VERSION ""

NS_ :

BS_:

BU_: FCM CGW EPS IPB TBOX
BO_ 773 FRM_3: 8 FCM
  SG_ FRM_3_VSetDis : 7|9@0+ (0.5,0) [0|255.5] "KPH" CGW
  SG_ FRM_3_DxTarObj : 14|3@0+ (1,0) [0|7] "Bit" CGW
  SG_ FRM_3_ObjValid : 8|1@0+ (1,0) [0|1] "Bit" CGW
  SG_ FRM_3_FrontObject_Type : 11|3@0+ (1,0) [0|7] "Bit" CGW
  SG_ FRM_3_Textinfo : 23|5@0+ (1,0) [0|31] "Bit" CGW
  SG_ FRM_3_TakeOverReq : 18|1@0+ (1,0) [0|1] "Bit" CGW
  SG_ FRM_3_TimeGapSet_ICM : 17|2@0+ (1,0) [0|3] "Bit" CGW
  SG_ FRM_3_ACCMode : 37|4@0+ (1,0) [0|15] "Bit" CGW
  SG_ FRM_3_Obiect_Dx : 29|8@0+ (0.5,0) [0|127] "M" CGW
  SG_ FRM_3_FCWMode : 33|3@0+ (1,0) [0|7] "Bit" CGW
  SG_ FRM_3_AEBMode : 46|3@0+ (1,0) [0|7] "Bit" CGW
  SG_ FRM_3_DistanceWarning : 43|1@0+ (1,0) [0|1] "Bit" CGW
  SG_ FRM_3_FCW_PreWarning : 42|1@0+ (1,0) [0|1] "Bit" CGW
  SG_ FRM_3_FCW_ON_OFF_Sts : 40|1@0+ (1,0) [0|1] "Bit" CGW
  SG_ FRM_3_FCW_OPTION_Sts : 55|2@0+ (1,0) [0|3] "Bit" CGW
  SG_ FRM_3_AEB_ON_OFF_Sts : 53|1@0+ (1,0) [0|1] "Bit" CGW
  SG_ FRM_3_MessageCounter : 51|4@0+ (1,0) [0|15] "Bit" CGW
  SG_ FRM_3_CRC : 63|8@0+ (1,0) [0|255] "Bit" CGW

BO_ 775 FCM_2: 8 FCM
  SG_ FCM_2_HMA_Status : 2|3@0+ (1,0) [0|7] "Bit" CGW
  SG_ FCM_2_HMA_HighbeamReq : 3|1@0+ (1,0) [0|1] "Bit" CGW
  SG_ FCM_2_HMAOnOffsts : 5|2@0+ (1,0) [0|3] "Bit" CGW
  SG_ FCM_2_LDW_LKA_LeftVisualization : 7|2@0+ (1,0) [0|3] "Bit" CGW
  SG_ FCM_2_LDW_LKA_RightVisualization : 15|2@0+ (1,0) [0|3] "Bit" CGW
  SG_ FCM_2_TrailorModeSts : 10|2@0+ (1,0) [0|3] "" CGW
  SG_ FCM_2_LDP_Status : 13|3@0+ (1,0) [0|7] "Bit" CGW
  SG_ FCM_2_LDWLKA_Sensitivityfeedback : 8|2@0+ (1,0) [0|3] "Bit" CGW
  SG_ FCM_2_SLAState : 21|3@0+ (1,0) [0|7] "Bit" CGW
  SG_ FCM_2_SLASpdlimit : 18|8@0+ (1,0) [0|255] "Bit" CGW
  SG_ FCM_2_SLAOnOffsts : 26|2@0+ (1,0) [0|3] "Bit" CGW
  SG_ FCM_2_SLASpdlimitWarning : 24|1@0+ (1,0) [0|1] "Bit" CGW
  SG_ FCM_2_Camera_Textinfo : 39|2@0+ (1,0) [0|3] "Bit" CGW
  SG_ FCM_2_ADAS_TakeoverReq : 37|2@0+ (1,0) [0|3] "Bit" CGW
  SG_ FCM_2_TJA_ICA_Textinfo : 34|3@0+ (1,0) [0|7] "Bit" CGW
  SG_ FCM_2_TJA_ICA_Mode : 47|3@0+ (1,0) [0|7] "Bit" CGW
  SG_ FCM_2_LDWOnOffSts : 43|2@0+ (1,0) [0|3] "Bit" CGW
  SG_ FCM_2_MessageCounter : 51|4@0+ (1,0) [0|15] "Bit" CGW
  SG_ FCM_2_weather_signal : 53|2@0+ (1,0) [0|3] "" CGW,TBOX
  SG_ FCM_2_CRCCheck : 63|8@0+ (1,0) [0|255] "Bit" CGW

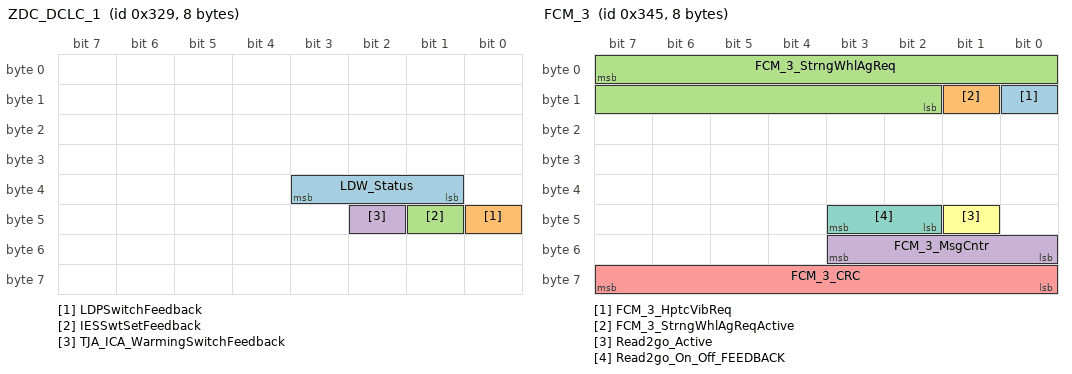
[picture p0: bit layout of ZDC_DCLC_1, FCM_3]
BO_ 809 ZDC_DCLC_1: 8 FCM
  SG_ LDW_Status : 35|3@0+ (1,0) [0|7] "Bit" Vector__XXX
  SG_ LDPSwitchFeedback : 40|1@0+ (1,0) [0|1] "Bit" Vector__XXX
  SG_ IESSwtSetFeedback : 41|1@0+ (1,0) [0|1] "Bit" Vector__XXX
  SG_ TJA_ICA_WarmingSwitchFeedback : 42|1@0+ (1,0) [0|1] "Bit" Vector__XXX

BO_ 837 FCM_3: 8 FCM
  SG_ FCM_3_HptcVibReq : 8|1@0+ (1,0) [0|1] "Bit" CGW,EPS
  SG_ FCM_3_StrngWhlAgReqActive : 9|1@0+ (1,0) [0|1] "Bit" EPS
  SG_ FCM_3_StrngWhlAgReq : 7|14@0+ (0.1,-780) [-780|780] "deg" EPS
  SG_ FCM_3_MsgCntr : 51|4@0+ (1,0) [0|15] "Bit" EPS
  SG_ FCM_3_CRC : 63|8@0+ (1,0) [0|255] "Bit" EPS,IPB
  SG_ Read2go_Active : 41|1@0+ (1,0) [0|1] "Bit" Vector__XXX
  SG_ Read2go_On_Off_FEEDBACK : 43|2@0+ (1,0) [0|3] "Bit" Vector__XXX

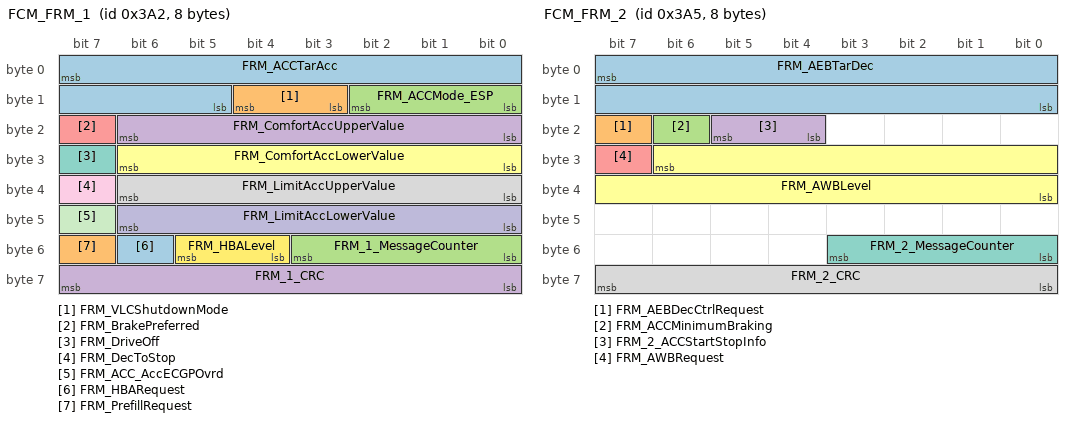
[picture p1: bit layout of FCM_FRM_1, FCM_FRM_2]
BO_ 930 FCM_FRM_1: 8 FCM
  SG_ FRM_ACCTarAcc : 7|11@0+ (0.005,-5) [-5|5.235] "M_S2" IPB
  SG_ FRM_VLCShutdownMode : 12|2@0+ (1,0) [0|3] "Bit" IPB
  SG_ FRM_ACCMode_ESP : 10|3@0+ (1,0) [0|7] "Bit" IPB
  SG_ FRM_ComfortAccUpperValue : 22|7@0+ (0.025,0) [0|3.125] "M_S2" IPB
  SG_ FRM_BrakePreferred : 23|1@0+ (1,0) [0|1] "Bit" IPB
  SG_ FRM_ComfortAccLowerValue : 30|7@0+ (0.025,0) [0|3.125] "M_S2" IPB
  SG_ FRM_DriveOff : 31|1@0+ (1,0) [0|1] "Bit" IPB
  SG_ FRM_LimitAccUpperValue : 38|7@0+ (0.1,0) [0|12.7] "M_S2" IPB
  SG_ FRM_DecToStop : 39|1@0+ (1,0) [0|1] "Bit" IPB
  SG_ FRM_LimitAccLowerValue : 46|7@0+ (0.1,-12.7) [-12.7|0] "M_S2" IPB
  SG_ FRM_ACC_AccECGPOvrd : 47|1@0+ (1,0) [0|1] "Bit" IPB
  SG_ FRM_HBALevel : 53|2@0+ (1,0) [0|3] "Bit" IPB
  SG_ FRM_HBARequest : 54|1@0+ (1,0) [0|1] "Bit" IPB
  SG_ FRM_PrefillRequest : 55|1@0+ (1,0) [0|1] "Bit" IPB
  SG_ FRM_1_MessageCounter : 51|4@0+ (1,0) [0|15] "Bit" IPB
  SG_ FRM_1_CRC : 63|8@0+ (1,0) [0|255] "Bit" IPB

BO_ 933 FCM_FRM_2: 8 FCM
  SG_ FRM_AEBTarDec : 7|16@0+ (0.0004882,-16) [-16|15.994187] "M_S2" IPB,CGW
  SG_ FRM_AEBDecCtrlRequest : 23|1@0+ (1,0) [0|1] "Bit" IPB,CGW
  SG_ FRM_ACCMinimumBraking : 22|1@0+ (1,0) [0|1] "Bit" IPB,CGW
  SG_ FRM_2_ACCStartStopInfo : 21|2@0+ (1,0) [0|3] "Bit" IPB,CGW
  SG_ FRM_AWBRequest : 31|1@0+ (1,0) [0|1] "Bit" IPB,CGW
  SG_ FRM_AWBLevel : 30|15@0+ (1,0) [0|15] "Bit" IPB,CGW
  SG_ FRM_2_MessageCounter : 51|4@0+ (1,0) [0|15] "Bit" IPB,CGW
  SG_ FRM_2_CRC : 63|8@0+ (1,0) [0|255] "Bit" IPB,CGW

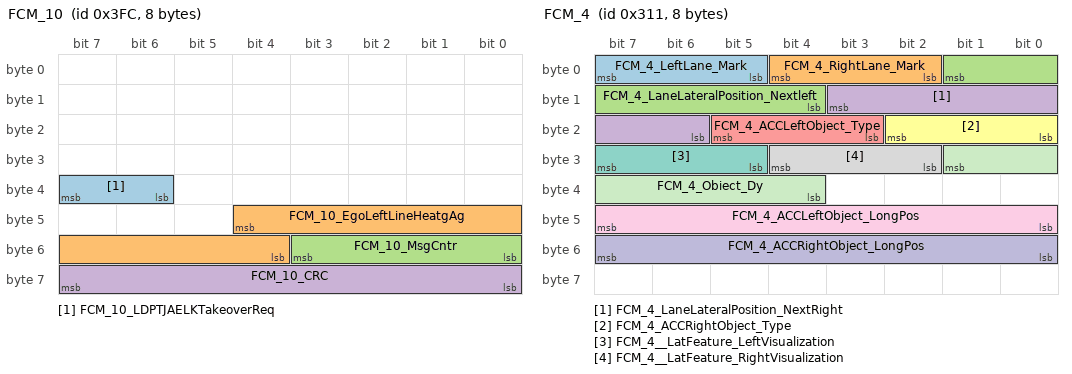
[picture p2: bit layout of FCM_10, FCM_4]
BO_ 1020 FCM_10: 8 FCM
  SG_ FCM_10_LDPTJAELKTakeoverReq : 39|2@0+ (1,0) [0|3] "Bit" CGW
  SG_ FCM_10_EgoLeftLineHeatgAg : 44|9@0+ (0.004,-1.02) [-1.02|1.02] "Rad" CGW
  SG_ FCM_10_MsgCntr : 51|4@0+ (1,0) [0|15] "Bit" CGW
  SG_ FCM_10_CRC : 63|8@0+ (1,0) [0|255] "Bit" CGW

BO_ 777 FCM_3_G: 8 FCM
  SG_ LaneCurvatureRadius : 7|11@0+ (0.00001,-0.01023) [-0.01023|0.01024] "Bit" CGW
  SG_ FCM_3_ACCLeftObjectDetected : 9|2@0+ (1,0) [0|3] "Bit" CGW
  SG_ FCM_3_ACCRightObjectDetected : 11|2@0+ (1,0) [0|3] "Bit" CGW
  SG_ FCM_3_ACCLeftObject_LatPos : 21|6@0+ (0.2,0) [0|12.6] "Bit" CGW
  SG_ FCM_3_ACCRightObject_LatPos : 29|6@0+ (0.2,0) [0|12.6] "Bit" CGW
  SG_ FCM_3_FrontObject_IndicatorRight : 22|1@0+ (1,0) [0|1] "Bit" CGW
  SG_ FCM_3_FrontObject_IndicatorLeft : 23|1@0+ (1,0) [0|1] "Bit" CGW
  SG_ FCM_3_FrontObject_BrakeLamp : 30|1@0+ (1,0) [0|1] "Bit" CGW
  SG_ FCM_3_LeftLane_C0 : 37|6@0+ (0.2,0) [0|12.6] "Bit" CGW
  SG_ FCM_3_RightLane_C0 : 47|6@0+ (0.2,0) [0|12.6] "Bit" CGW
  SG_ FCM_3_NoLeftTurn_sign : 38|1@0+ (1,0) [0|1] "Bit" CGW
  SG_ FCM_3_NoRightTurn_sign : 39|1@0+ (1,0) [0|1] "Bit" CGW
  SG_ FCM_3_StopSign : 31|1@0+ (1,0) [0|1] "Bit" CGW
  SG_ FCM_3_NOU_turnsign : 41|1@0+ (1,0) [0|1] "Bit" CGW
  SG_ FCM_3_Noentrysign : 40|1@0+ (1,0) [0|1] "Bit" CGW
  SG_ FCM_3_Constructionareasign : 55|1@0+ (1,0) [0|1] "Bit" CGW
  SG_ FCM_3_Crossingsign : 54|1@0+ (1,0) [0|1] "Bit" CGW
  SG_ FCM_3_YieldSIgn : 53|1@0+ (1,0) [0|1] "Bit" CGW
  SG_ FCM_3_NextLeftLane_Mark : 58|3@0+ (1,0) [0|7] "Bit" CGW
  SG_ FCM_3_NextRightLane_Mark : 61|3@0+ (1,0) [0|7] "Bit" CGW

BO_ 785 FCM_4: 8 FCM
  SG_ FCM_4_LeftLane_Mark : 7|3@0+ (1,0) [0|7] "Bit" CGW
  SG_ FCM_4_RightLane_Mark : 4|3@0+ (1,0) [0|7] "Bit" CGW
  SG_ FCM_4_LaneLateralPosition_Nextleft : 1|6@0+ (0.2,0) [0|12.6] "Bit" CGW
  SG_ FCM_4_LaneLateralPosition_NextRight : 11|6@0+ (0.2,0) [0|12.6] "Bit" CGW
  SG_ FCM_4_ACCLeftObject_Type : 21|3@0+ (1,0) [0|7] "Bit" CGW
  SG_ FCM_4_ACCRightObject_Type : 18|3@0+ (1,0) [0|7] "Bit" CGW
  SG_ FCM_4__LatFeature_LeftVisualization : 31|3@0+ (1,0) [0|7] "Bit" CGW
  SG_ FCM_4__LatFeature_RightVisualization : 28|3@0+ (1,0) [0|7] "Bit" CGW
  SG_ FCM_4_ACCLeftObject_LongPos : 47|8@0+ (1,0) [0|255] "Bit" CGW
  SG_ FCM_4_ACCRightObject_LongPos : 55|8@0+ (1,0) [0|255] "Bit" CGW
  SG_ FCM_4_Obiect_Dy : 25|6@0+ (0.1,-3.2) [-3.2|3.1] "M" CGW

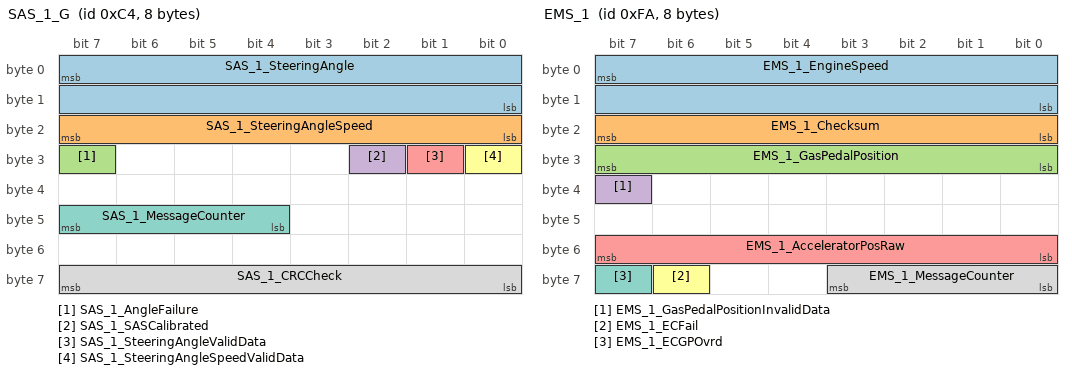
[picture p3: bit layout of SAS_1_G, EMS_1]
BO_ 196 SAS_1_G: 8 CGW
  SG_ SAS_1_SteeringAngle : 7|16@0+ (0.0625,-2048) [-2048|2047.9375] "Deg" FCM
  SG_ SAS_1_SteeringAngleSpeed : 23|8@0+ (4,0) [0|1016] "Deg_Sec" FCM
  SG_ SAS_1_AngleFailure : 31|1@0+ (1,0) [0|1] "Bit" FCM
  SG_ SAS_1_SASCalibrated : 26|1@0+ (1,0) [0|1] "Bit" FCM
  SG_ SAS_1_SteeringAngleValidData : 25|1@0+ (1,0) [0|1] "Bit" FCM
  SG_ SAS_1_SteeringAngleSpeedValidData : 24|1@0+ (1,0) [0|1] "Bit" FCM
  SG_ SAS_1_MessageCounter : 47|4@0+ (1,0) [0|15] "Bit" FCM
  SG_ SAS_1_CRCCheck : 63|8@0+ (1,0) [0|255] "Bit" FCM

BO_ 250 EMS_1: 8 CGW
  SG_ EMS_1_EngineSpeed : 7|16@0+ (0.25,0) [0|16383] "Rpm" FCM
  SG_ EMS_1_Checksum : 23|8@0+ (1,0) [0|255] "Bit" FCM
  SG_ EMS_1_GasPedalPosition : 31|8@0+ (0.392,0) [0|99.568] "%" FCM
  SG_ EMS_1_GasPedalPositionInvalidData : 39|1@0+ (1,0) [0|1] "Bit" FCM
  SG_ EMS_1_AcceleratorPosRaw : 55|8@0+ (0.392,0) [0|99.568] "%" FCM
  SG_ EMS_1_ECFail : 62|1@0+ (1,0) [0|1] "Bit" FCM
  SG_ EMS_1_ECGPOvrd : 63|1@0+ (1,0) [0|1] "Bit" FCM
  SG_ EMS_1_MessageCounter : 59|4@0+ (1,0) [0|15] "Bit" FCM

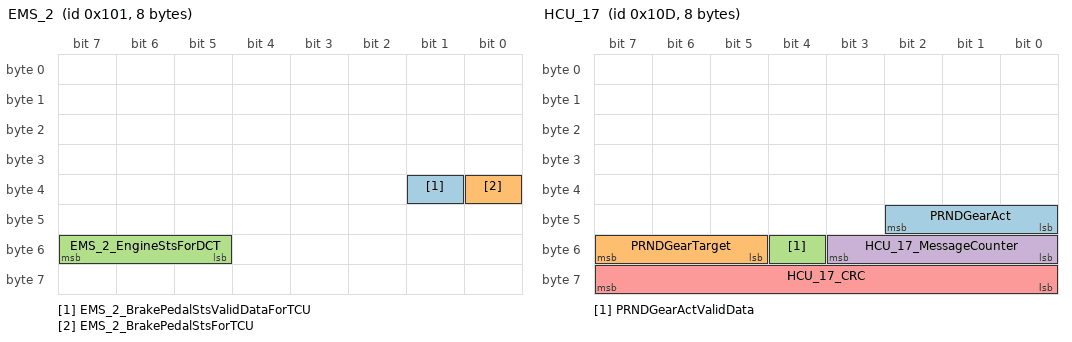
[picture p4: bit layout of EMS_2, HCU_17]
BO_ 257 EMS_2: 8 CGW
  SG_ EMS_2_BrakePedalStsValidDataForTCU : 33|1@0+ (1,0) [0|1] "Bit" FCM
  SG_ EMS_2_BrakePedalStsForTCU : 32|1@0+ (1,0) [0|1] "Bit" FCM
  SG_ EMS_2_EngineStsForDCT : 55|3@0+ (1,0) [0|7] "Bit" FCM

BO_ 269 HCU_17: 8 CGW
  SG_ PRNDGearAct : 42|3@0+ (1,0) [0|7] "Bit" FCM
  SG_ PRNDGearTarget : 55|3@0+ (1,0) [0|7] "Bit" FCM
  SG_ PRNDGearActValidData : 52|1@0+ (1,0) [0|1] "Bit" FCM
  SG_ HCU_17_MessageCounter : 51|4@0+ (1,0) [0|15] "Bit" FCM
  SG_ HCU_17_CRC : 63|8@0+ (1,0) [0|255] "Bit" FCM

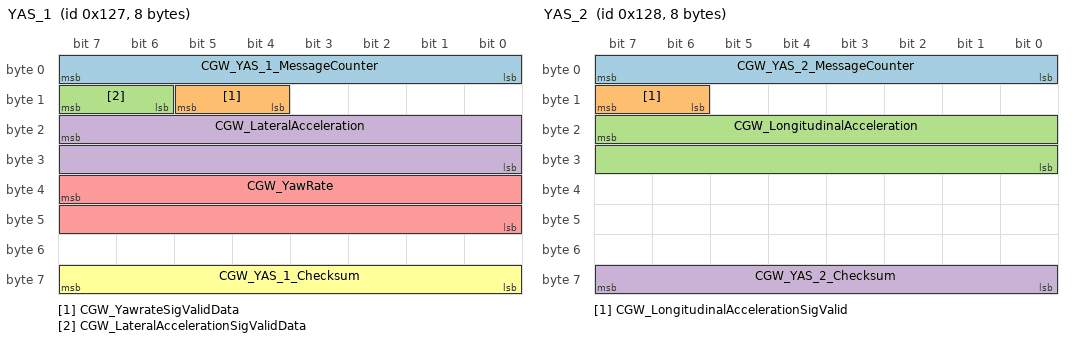
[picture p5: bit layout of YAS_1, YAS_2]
BO_ 295 YAS_1: 8 CGW
  SG_ CGW_YAS_1_MessageCounter : 7|8@0+ (1,0) [0|255] "Bit" FCM
  SG_ CGW_YawrateSigValidData : 13|2@0+ (1,0) [0|3] "Bit" FCM
  SG_ CGW_LateralAccelerationSigValidData : 15|2@0+ (1,0) [0|3] "Bit" FCM
  SG_ CGW_LateralAcceleration : 23|16@0+ (0.001,-2) [-2|2] "G" FCM
  SG_ CGW_YawRate : 39|16@0+ (0.01,-180) [-180|180] "Deg/sec" FCM
  SG_ CGW_YAS_1_Checksum : 63|8@0+ (1,0) [0|255] "Bit" FCM

BO_ 296 YAS_2: 8 CGW
  SG_ CGW_YAS_2_MessageCounter : 7|8@0+ (1,0) [0|255] "Bit" FCM
  SG_ CGW_LongitudinalAccelerationSigValid : 15|2@0+ (1,0) [0|3] "Bit" FCM
  SG_ CGW_LongitudinalAcceleration : 23|16@0+ (0.001,-2) [-2|2] "G" FCM
  SG_ CGW_YAS_2_Checksum : 63|8@0+ (1,0) [0|255] "Bit" FCM

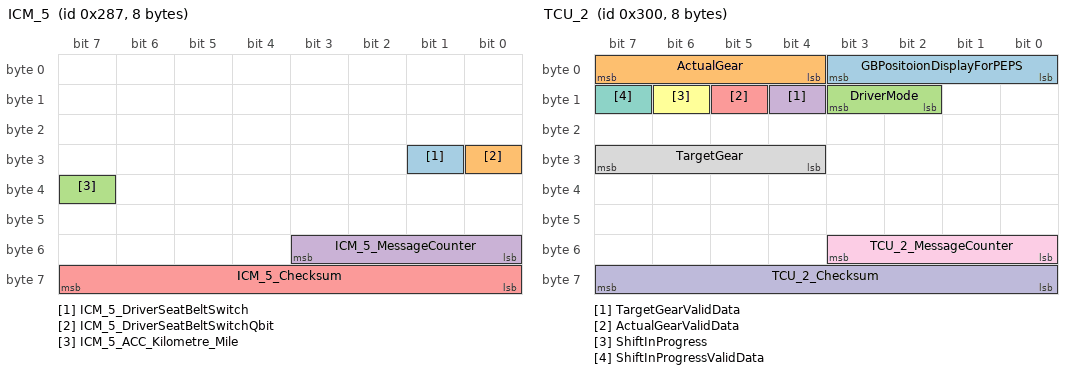
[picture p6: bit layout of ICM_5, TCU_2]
BO_ 647 ICM_5: 8 CGW
  SG_ ICM_5_DriverSeatBeltSwitch : 25|1@0+ (1,0) [0|1] "Bit" FCM
  SG_ ICM_5_DriverSeatBeltSwitchQbit : 24|1@0+ (1,0) [0|1] "Bit" FCM
  SG_ ICM_5_ACC_Kilometre_Mile : 39|1@0+ (1,0) [0|1] "Bit" FCM
  SG_ ICM_5_MessageCounter : 51|4@0+ (1,0) [0|15] "Bit" FCM
  SG_ ICM_5_Checksum : 63|8@0+ (1,0) [0|255] "Bit" FCM

BO_ 768 TCU_2: 8 CGW
  SG_ GBPositoionDisplayForPEPS : 3|4@0+ (1,0) [0|15] "Bit" FCM
  SG_ ActualGear : 7|4@0+ (1,0) [0|15] "Bit" FCM
  SG_ DriverMode : 11|2@0+ (1,0) [0|3] "Bit" FCM
  SG_ TargetGearValidData : 12|1@0+ (1,0) [0|1] "Bit" FCM
  SG_ ActualGearValidData : 13|1@0+ (1,0) [0|1] "Bit" FCM
  SG_ ShiftInProgress : 14|1@0+ (1,0) [0|1] "Bit" FCM
  SG_ ShiftInProgressValidData : 15|1@0+ (1,0) [0|1] "Bit" FCM
  SG_ TargetGear : 31|4@0+ (1,0) [0|15] "Bit" FCM
  SG_ TCU_2_MessageCounter : 51|4@0+ (1,0) [0|15] "Bit" FCM
  SG_ TCU_2_Checksum : 63|8@0+ (1,0) [0|255] "Bit" FCM

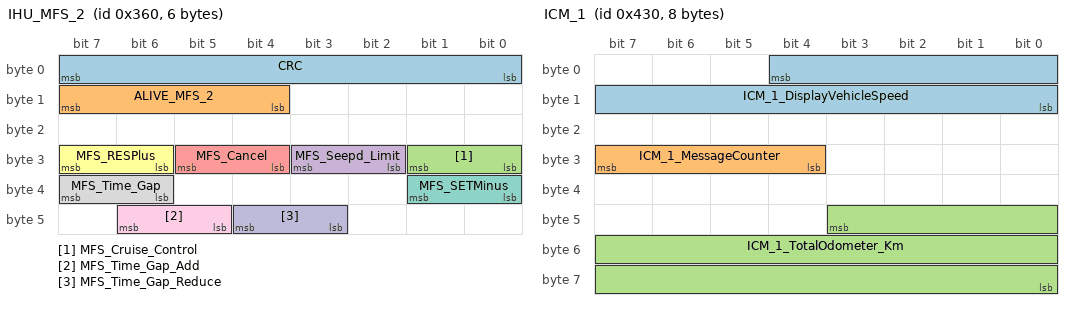
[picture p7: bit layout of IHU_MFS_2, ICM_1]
BO_ 864 IHU_MFS_2: 6 CGW
  SG_ CRC : 7|8@0+ (1,0) [0|255] "Bit" FCM
  SG_ ALIVE_MFS_2 : 15|4@0+ (1,0) [0|15] "Bit" FCM
  SG_ MFS_Cruise_Control : 25|2@0+ (1,0) [0|3] "Bit" FCM
  SG_ MFS_Seepd_Limit : 27|2@0+ (1,0) [0|3] "Bit" FCM
  SG_ MFS_Cancel : 29|2@0+ (1,0) [0|3] "Bit" FCM
  SG_ MFS_RESPlus : 31|2@0+ (1,0) [0|3] "Bit" FCM
  SG_ MFS_SETMinus : 33|2@0+ (1,0) [0|3] "Bit" FCM
  SG_ MFS_Time_Gap : 39|2@0+ (1,0) [0|3] "Bit" FCM
  SG_ MFS_Time_Gap_Add : 46|2@0+ (1,0) [0|3] "Bit" FCM
  SG_ MFS_Time_Gap_Reduce : 44|2@0+ (1,0) [0|3] "Bit" FCM

BO_ 913 BCM_1: 8 CGW
  SG_ BCM_1_HighBeamSts : 2|1@0+ (1,0) [0|1] "Bit" FCM
  SG_ BCM_1_LowBeamSts : 3|1@0+ (1,0) [0|1] "Bit" FCM
  SG_ BCM_1_KeySts : 6|2@0+ (1,0) [0|3] "Bit" FCM
  SG_ BCM_1_Checksum : 15|8@0+ (1,0) [0|255] "Bit" FCM
  SG_ BCM_1_DirectionIndRight : 16|1@0+ (1,0) [0|1] "Bit" FCM
  SG_ BCM_1_DirectionIndLeft : 17|1@0+ (1,0) [0|1] "Bit" FCM
  SG_ BCM_1_HazardLightSW : 18|1@0+ (1,0) [0|1] "Bit" FCM
  SG_ BCM_1_AutoLightSW : 19|1@0+ (1,0) [0|1] "Bit" FCM
  SG_ BCM_1_DriverDoorSts : 24|1@0+ (1,0) [0|1] "Bit" FCM
  SG_ BCM_1_PsngrDoorSts : 25|1@0+ (1,0) [0|1] "Bit" FCM
  SG_ BCM_1_HoodSts : 26|1@0+ (1,0) [0|1] "Bit" FCM
  SG_ BCM_1_RHRDoorSts : 28|1@0+ (1,0) [0|1] "Bit" FCM
  SG_ BCM_1_LHRdoorSts : 29|1@0+ (1,0) [0|1] "Bit" FCM
  SG_ BCM_1_TrunkSts : 30|1@0+ (1,0) [0|1] "Bit" FCM
  SG_ BCM_1_DriverDoorStsQbit : 31|1@0+ (1,0) [0|1] "Bit" FCM
  SG_ BCM_1_HMASW : 32|1@0+ (1,0) [0|1] "Bit" FCM
  SG_ BCM_1_FrontFogLightSts : 37|1@0+ (1,0) [0|1] "Bit" FCM
  SG_ BCM_1_HighBeamSWSts : 38|1@0+ (1,0) [0|1] "Bit" FCM
  SG_ BCM_1_FlashSWSts : 39|1@0+ (1,0) [0|1] "Bit" FCM
  SG_ BCM_1_WiperSts : 47|2@0+ (1,0) [0|3] "Bit" FCM
  SG_ BCM_1_AutoHighSpeedRequest : 52|1@0+ (1,0) [0|1] "Bit" FCM
  SG_ BCM_1_RainDetected : 53|1@0+ (1,0) [0|1] "Bit" FCM
  SG_ BCM_1_MessageCounter : 51|4@0+ (1,0) [0|15] "Bit" FCM

BO_ 1034 HCU_1_G: 8 CGW
  SG_ HCU_PTReady : 49|1@0+ (1,0) [0|1] "Bit" FCM

BO_ 1072 ICM_1: 8 CGW
  SG_ ICM_1_DisplayVehicleSpeed : 4|13@0+ (0.0625,0) [0|511.875] "Km/h" FCM
  SG_ ICM_1_MessageCounter : 31|4@0+ (1,0) [0|15] "Bit" FCM
  SG_ ICM_1_TotalOdometer_Km : 43|20@0+ (1,0) [0|999999] "Km" FCM

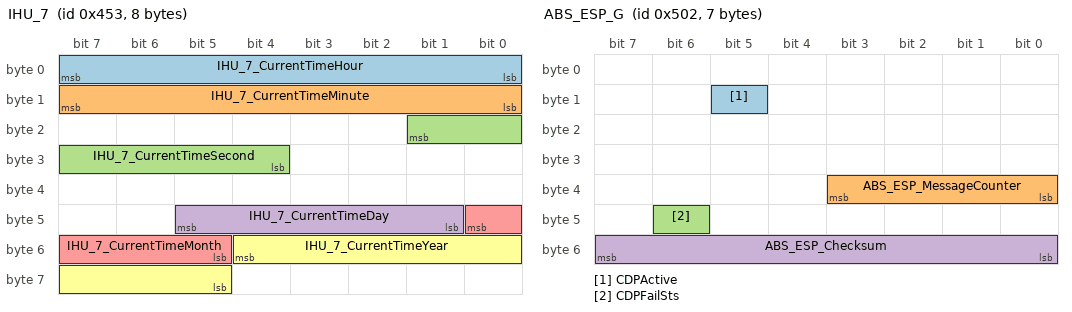
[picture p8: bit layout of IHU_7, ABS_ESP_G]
BO_ 1107 IHU_7: 8 CGW
  SG_ IHU_7_CurrentTimeHour : 7|8@0+ (1,0) [0|23] "Hour" FCM
  SG_ IHU_7_CurrentTimeMinute : 15|8@0+ (1,0) [0|59] "Minute" FCM
  SG_ IHU_7_CurrentTimeSecond : 17|6@0+ (1,0) [0|59] "Second" FCM
  SG_ IHU_7_CurrentTimeDay : 45|5@0+ (1,0) [1|31] "Day" FCM
  SG_ IHU_7_CurrentTimeMonth : 40|4@0+ (1,0) [0|12] "Month" FCM
  SG_ IHU_7_CurrentTimeYear : 52|8@0+ (1,2000) [2000|2255] "Year" FCM

BO_ 1282 ABS_ESP_G: 7 CGW
  SG_ CDPActive : 13|1@0+ (1,0) [0|1] "Bit" FCM
  SG_ ABS_ESP_MessageCounter : 35|4@0+ (1,0) [0|15] "Bit" FCM
  SG_ CDPFailSts : 46|1@0+ (1,0) [0|1] "Bit" FCM
  SG_ ABS_ESP_Checksum : 55|8@0+ (1,0) [0|255] "Bit" FCM

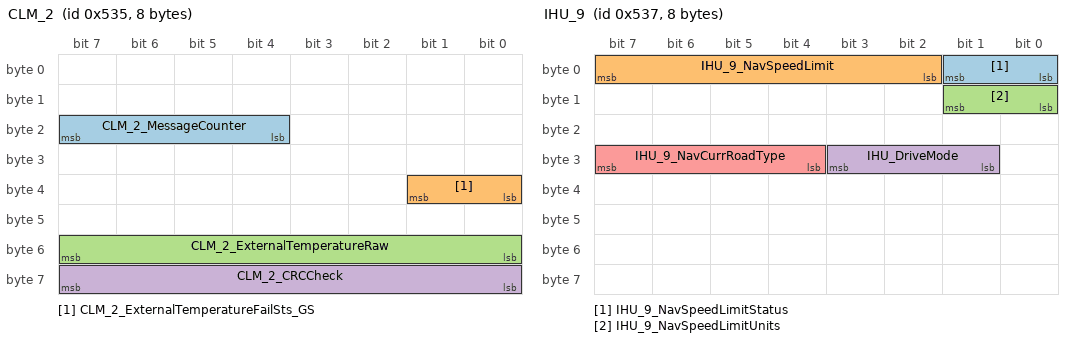
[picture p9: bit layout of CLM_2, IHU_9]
BO_ 1333 CLM_2: 8 CGW
  SG_ CLM_2_MessageCounter : 23|4@0+ (1,0) [0|15] "Bit" FCM
  SG_ CLM_2_ExternalTemperatureFailSts_GS : 33|2@0+ (1,0) [0|3] "Bit" FCM
  SG_ CLM_2_ExternalTemperatureRaw : 55|8@0+ (0.5,-40) [-40|85] "Nm" FCM
  SG_ CLM_2_CRCCheck : 63|8@0+ (1,0) [0|255] "Bit" FCM

BO_ 1335 IHU_9: 8 CGW
  SG_ IHU_9_NavSpeedLimitStatus : 1|2@0+ (1,0) [0|3] "Bit" FCM
  SG_ IHU_9_NavSpeedLimit : 7|6@0+ (1,0) [0|63] "Bit" FCM
  SG_ IHU_9_NavSpeedLimitUnits : 9|2@0+ (1,0) [0|3] "Bit" FCM
  SG_ IHU_DriveMode : 27|3@0+ (1,0) [0|7] "Bit" FCM
  SG_ IHU_9_NavCurrRoadType : 31|4@0+ (1,0) [0|15] "Bit" FCM

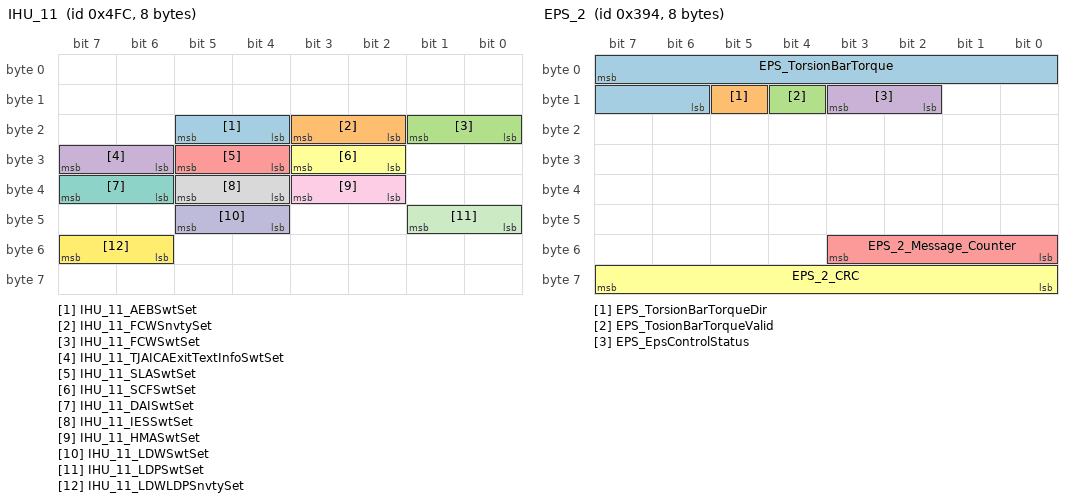
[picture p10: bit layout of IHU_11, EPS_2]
BO_ 1276 IHU_11: 8 CGW
  SG_ IHU_11_AEBSwtSet : 21|2@0+ (1,0) [0|3] "Bit" FCM
  SG_ IHU_11_FCWSnvtySet : 19|2@0+ (1,0) [0|3] "Bit" FCM
  SG_ IHU_11_FCWSwtSet : 17|2@0+ (1,0) [0|3] "Bit" FCM
  SG_ IHU_11_TJAICAExitTextInfoSwtSet : 31|2@0+ (1,0) [0|3] "Bit" FCM
  SG_ IHU_11_SLASwtSet : 29|2@0+ (1,0) [0|3] "Bit" FCM
  SG_ IHU_11_SCFSwtSet : 27|2@0+ (1,0) [0|3] "Bit" FCM
  SG_ IHU_11_DAISwtSet : 39|2@0+ (1,0) [0|3] "Bit" FCM
  SG_ IHU_11_IESSwtSet : 37|2@0+ (1,0) [0|3] "Bit" FCM
  SG_ IHU_11_HMASwtSet : 35|2@0+ (1,0) [0|3] "Bit" FCM
  SG_ IHU_11_LDWSwtSet : 45|2@0+ (1,0) [0|3] "Bit" FCM
  SG_ IHU_11_LDPSwtSet : 41|2@0+ (1,0) [0|3] "Bit" FCM
  SG_ IHU_11_LDWLDPSnvtySet : 55|2@0+ (1,0) [0|3] "Bit" FCM

BO_ 932 ABS_ESP_18: 8 CGW
  SG_ ESP_18_CCO_Active : 1|2@0+ (1,0) [0|3] "" FCM

BO_ 1487 TRM_1: 8 CGW
  SG_ TRM_1_MotorHomeConnectSts : 6|1@0+ (1,0) [0|1] "Bit" FCM
  SG_ TRM_1_RollingCounter : 51|4@0+ (1,0) [0|15] "" FCM

BO_ 916 EPS_2: 8 EPS
  SG_ EPS_TorsionBarTorque : 7|10@0+ (0.01,0) [0|10.22] "Nm" FCM
  SG_ EPS_TorsionBarTorqueDir : 13|1@0+ (1,0) [0|1] "Bit" FCM
  SG_ EPS_TosionBarTorqueValid : 12|1@0+ (1,0) [0|1] "Bit" FCM
  SG_ EPS_EpsControlStatus : 11|2@0+ (1,0) [0|3] "Bit" FCM
  SG_ EPS_2_Message_Counter : 51|4@0+ (1,0) [0|15] "Bit" FCM
  SG_ EPS_2_CRC : 63|8@0+ (1,0) [0|255] "Bit" FCM

BO_ 1285 EPS_1: 3 EPS
  SG_ EPS_1_EPS_AssistanceStyleSts : 6|2@0+ (1,0) [0|3] "Bit" FCM

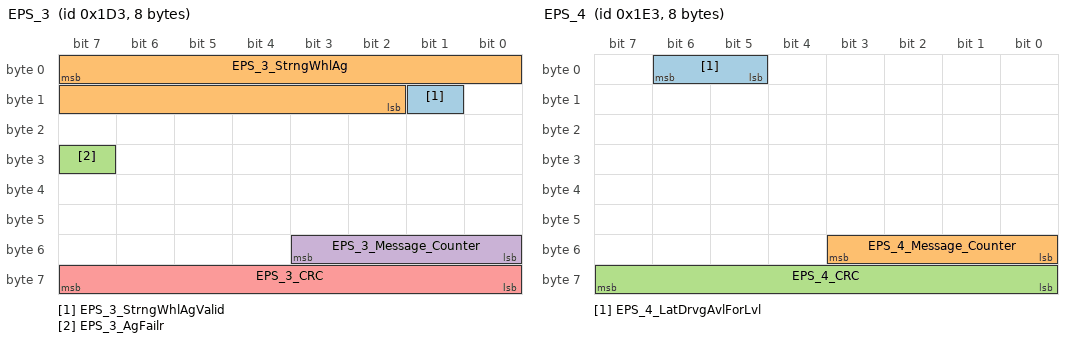
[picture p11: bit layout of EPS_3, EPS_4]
BO_ 467 EPS_3: 8 EPS
  SG_ EPS_3_StrngWhlAgValid : 9|1@0+ (1,0) [0|1] "Bit" FCM
  SG_ EPS_3_StrngWhlAg : 7|14@0+ (0.1,-780) [-780|780] "Bit" FCM
  SG_ EPS_3_AgFailr : 31|1@0+ (1,0) [0|1] "Bit" FCM
  SG_ EPS_3_Message_Counter : 51|4@0+ (1,0) [0|15] "Bit" FCM
  SG_ EPS_3_CRC : 63|8@0+ (1,0) [0|255] "Bit" FCM

BO_ 483 EPS_4: 8 EPS
  SG_ EPS_4_LatDrvgAvlForLvl : 6|2@0+ (1,0) [0|3] "Bit" FCM
  SG_ EPS_4_Message_Counter : 51|4@0+ (1,0) [0|15] "Bit" FCM
  SG_ EPS_4_CRC : 63|8@0+ (1,0) [0|255] "Bit" FCM

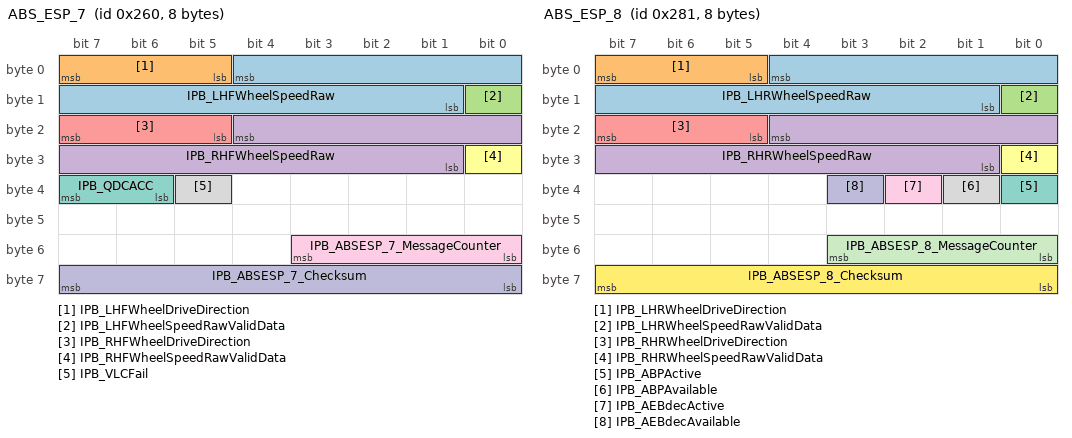
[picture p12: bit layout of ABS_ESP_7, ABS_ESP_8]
BO_ 608 ABS_ESP_7: 8 IPB
  SG_ IPB_LHFWheelSpeedRaw : 4|12@0+ (0.05,-30) [-30|80] "M/s" FCM
  SG_ IPB_LHFWheelDriveDirection : 7|3@0+ (1,0) [0|7] "Bit" FCM
  SG_ IPB_LHFWheelSpeedRawValidData : 8|1@0+ (1,0) [0|1] "Bit" FCM
  SG_ IPB_RHFWheelSpeedRaw : 20|12@0+ (0.05,-30) [-30|80] "M/s" FCM
  SG_ IPB_RHFWheelDriveDirection : 23|3@0+ (1,0) [0|7] "Bit" FCM
  SG_ IPB_RHFWheelSpeedRawValidData : 24|1@0+ (1,0) [0|1] "Bit" FCM
  SG_ IPB_QDCACC : 39|2@0+ (1,0) [0|3] "Bit" FCM
  SG_ IPB_VLCFail : 37|1@0+ (1,0) [0|1] "Bit" FCM
  SG_ IPB_ABSESP_7_MessageCounter : 51|4@0+ (1,0) [0|15] "Bit" FCM
  SG_ IPB_ABSESP_7_Checksum : 63|8@0+ (1,0) [0|255] "Bit" FCM

BO_ 641 ABS_ESP_8: 8 IPB
  SG_ IPB_LHRWheelSpeedRaw : 4|12@0+ (0.05,-30) [-30|80] "M/s" FCM
  SG_ IPB_LHRWheelDriveDirection : 7|3@0+ (1,0) [0|7] "Bit" FCM
  SG_ IPB_LHRWheelSpeedRawValidData : 8|1@0+ (1,0) [0|1] "Bit" FCM
  SG_ IPB_RHRWheelSpeedRaw : 20|12@0+ (0.05,-30) [-30|80] "M/s" FCM
  SG_ IPB_RHRWheelDriveDirection : 23|3@0+ (1,0) [0|7] "Bit" FCM
  SG_ IPB_RHRWheelSpeedRawValidData : 24|1@0+ (1,0) [0|1] "Bit" FCM
  SG_ IPB_ABPActive : 32|1@0+ (1,0) [0|1] "Bit" FCM
  SG_ IPB_ABPAvailable : 33|1@0+ (1,0) [0|1] "Bit" FCM
  SG_ IPB_AEBdecActive : 34|1@0+ (1,0) [0|1] "Bit" FCM
  SG_ IPB_AEBdecAvailable : 35|1@0+ (1,0) [0|1] "Bit" FCM
  SG_ IPB_ABSESP_8_MessageCounter : 51|4@0+ (1,0) [0|15] "Bit" FCM
  SG_ IPB_ABSESP_8_Checksum : 63|8@0+ (1,0) [0|255] "Bit" FCM

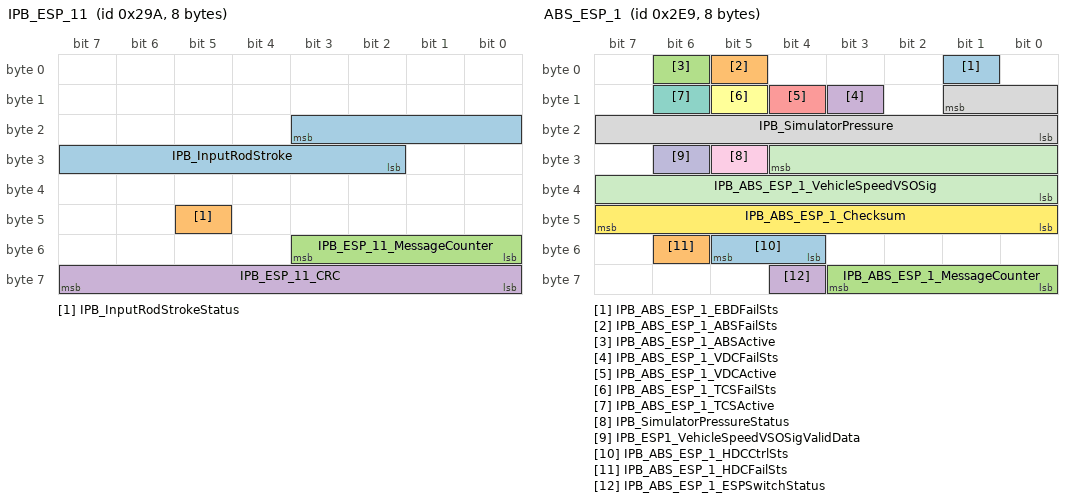
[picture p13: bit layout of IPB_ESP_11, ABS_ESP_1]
BO_ 666 IPB_ESP_11: 8 IPB
  SG_ IPB_InputRodStroke : 19|10@0+ (0.05,-5) [-5|46.15] "Mm" FCM
  SG_ IPB_InputRodStrokeStatus : 45|1@0+ (1,0) [0|1] "Bit" FCM
  SG_ IPB_ESP_11_MessageCounter : 51|4@0+ (1,0) [0|15] "Bit" FCM
  SG_ IPB_ESP_11_CRC : 63|8@0+ (1,0) [0|255] "Bit" FCM

BO_ 745 ABS_ESP_1: 8 IPB
  SG_ IPB_ABS_ESP_1_EBDFailSts : 1|1@0+ (1,0) [0|1] "Bit" FCM
  SG_ IPB_ABS_ESP_1_ABSFailSts : 5|1@0+ (1,0) [0|1] "Bit" FCM
  SG_ IPB_ABS_ESP_1_ABSActive : 6|1@0+ (1,0) [0|1] "Bit" FCM
  SG_ IPB_ABS_ESP_1_VDCFailSts : 11|1@0+ (1,0) [0|1] "Bit" FCM
  SG_ IPB_ABS_ESP_1_VDCActive : 12|1@0+ (1,0) [0|1] "Bit" FCM
  SG_ IPB_ABS_ESP_1_TCSFailSts : 13|1@0+ (1,0) [0|1] "Bit" FCM
  SG_ IPB_ABS_ESP_1_TCSActive : 14|1@0+ (1,0) [0|1] "Bit" FCM
  SG_ IPB_SimulatorPressure : 9|10@0+ (1,0) [0|1022] "Bar" FCM
  SG_ IPB_SimulatorPressureStatus : 29|1@0+ (1,0) [0|1] "Bit" FCM
  SG_ IPB_ESP1_VehicleSpeedVSOSigValidData : 30|1@0+ (1,0) [0|1] "Bit" FCM
  SG_ IPB_ABS_ESP_1_VehicleSpeedVSOSig : 28|13@0+ (0.0625,0) [0|511.875] "Km/h" FCM
  SG_ IPB_ABS_ESP_1_Checksum : 47|8@0+ (1,0) [0|255] "Bit" FCM
  SG_ IPB_ABS_ESP_1_HDCCtrlSts : 53|2@0+ (1,0) [0|3] "Bit" FCM
  SG_ IPB_ABS_ESP_1_HDCFailSts : 54|1@0+ (1,0) [0|1] "Bit" FCM
  SG_ IPB_ABS_ESP_1_MessageCounter : 59|4@0+ (1,0) [0|15] "Bit" FCM
  SG_ IPB_ABS_ESP_1_ESPSwitchStatus : 60|1@0+ (1,0) [0|1] "Bit" FCM

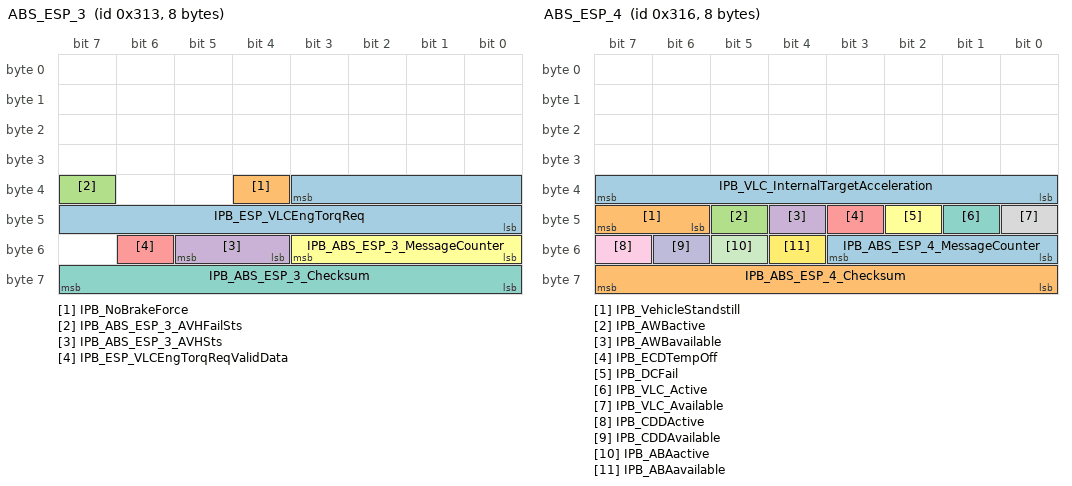
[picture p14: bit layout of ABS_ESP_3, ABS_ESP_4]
BO_ 787 ABS_ESP_3: 8 IPB
  SG_ IPB_ESP_VLCEngTorqReq : 35|12@0+ (0.5,-1000) [-1000|1000] "NM" FCM
  SG_ IPB_NoBrakeForce : 36|1@0+ (1,0) [0|1] "Bit" FCM
  SG_ IPB_ABS_ESP_3_AVHFailSts : 39|1@0+ (1,0) [0|1] "Bit" FCM
  SG_ IPB_ABS_ESP_3_AVHSts : 53|2@0+ (1,0) [0|3] "Bit" FCM
  SG_ IPB_ESP_VLCEngTorqReqValidData : 54|1@0+ (1,0) [0|1] "Bit" FCM
  SG_ IPB_ABS_ESP_3_MessageCounter : 51|4@0+ (1,0) [0|15] "Bit" FCM
  SG_ IPB_ABS_ESP_3_Checksum : 63|8@0+ (1,0) [0|255] "Bit" FCM

BO_ 790 ABS_ESP_4: 8 IPB
  SG_ IPB_VLC_InternalTargetAcceleration : 39|8@0+ (0.05,-7) [-7|5.75] "M/s2" FCM
  SG_ IPB_VehicleStandstill : 47|2@0+ (1,0) [0|3] "Bit" FCM
  SG_ IPB_AWBactive : 45|1@0+ (1,0) [0|1] "Bit" FCM
  SG_ IPB_AWBavailable : 44|1@0+ (1,0) [0|1] "Bit" FCM
  SG_ IPB_ECDTempOff : 43|1@0+ (1,0) [0|1] "Bit" FCM
  SG_ IPB_DCFail : 42|1@0+ (1,0) [0|1] "Bit" FCM
  SG_ IPB_VLC_Active : 41|1@0+ (1,0) [0|1] "Bit" FCM
  SG_ IPB_VLC_Available : 40|1@0+ (1,0) [0|1] "Bit" FCM
  SG_ IPB_CDDActive : 55|1@0+ (1,0) [0|1] "Bit" FCM
  SG_ IPB_CDDAvailable : 54|1@0+ (1,0) [0|1] "Bit" FCM
  SG_ IPB_ABAactive : 53|1@0+ (1,0) [0|1] "Bit" FCM
  SG_ IPB_ABAavailable : 52|1@0+ (1,0) [0|1] "Bit" FCM
  SG_ IPB_ABS_ESP_4_MessageCounter : 51|4@0+ (1,0) [0|15] "Bit" FCM
  SG_ IPB_ABS_ESP_4_Checksum : 63|8@0+ (1,0) [0|255] "Bit" FCM

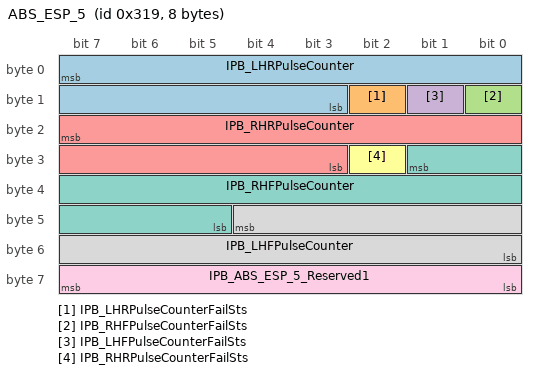
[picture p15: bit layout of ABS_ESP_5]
BO_ 793 ABS_ESP_5: 8 IPB
  SG_ IPB_LHRPulseCounter : 7|13@0+ (1,0) [0|8191] "Pulse" FCM
  SG_ IPB_LHRPulseCounterFailSts : 10|1@0+ (1,0) [0|1] "Bit" FCM
  SG_ IPB_RHFPulseCounterFailSts : 8|1@0+ (1,0) [0|1] "Bit" FCM
  SG_ IPB_LHFPulseCounterFailSts : 9|1@0+ (1,0) [0|1] "Bit" FCM
  SG_ IPB_RHRPulseCounter : 23|13@0+ (1,0) [0|8191] "Pulse" FCM
  SG_ IPB_RHRPulseCounterFailSts : 26|1@0+ (1,0) [0|1] "Bit" FCM
  SG_ IPB_RHFPulseCounter : 25|13@0+ (1,0) [0|8191] "Pulse" FCM
  SG_ IPB_LHFPulseCounter : 44|13@0+ (1,0) [0|8191] "Pulse" FCM
  SG_ IPB_ABS_ESP_5_Reserved1 : 63|8@0+ (1,0) [0|0] "Bit" FCM

BO_ 1270 EPB_G: 2 IPB
  SG_ IPB_EPBErrorStatus : 3|1@0+ (1,0) [0|1] "Bit" FCM
  SG_ IPB_EPBStatus : 7|3@0+ (1,0) [0|7] "Bit" FCM

CM_ SG_ 775 FCM_2_SLAState "FCM发状态值对应
0x0:Off
0x1:Fusion_mode
0x2:Vision_mode
0x3:Navigation_only_mode
0x4:Defect
0x5~0x7:Reserved
ZDC发，状态值对应
0x0:Off
0x1:Standby
0x2:Active
0x3:Reserved
0x4:Failure
0x5~0x7:Reserved";
CM_ SG_ 837 FCM_3_HptcVibReq "Vibration_request_flag_for_steering_wheel_angle
";
CM_ SG_ 837 FCM_3_StrngWhlAgReqActive "DADC_request_flag_for_steering_wheel_angle_control_to_be_enabled";
CM_ SG_ 837 FCM_3_StrngWhlAgReq "DADC_request_for_steering_wheel_angle,_steering_wheel_angle_request._";
CM_ SG_ 837 FCM_3_MsgCntr "Rolling_message_counter(the_maximum_value_of_Alive_counter_is_15)
Note:_Details_Please_refer_to_specification《EE_Standard_Specification_for_CAN_FD_Network_Implementation》section_2.3.1
";
CM_ SG_ 837 FCM_3_CRC "CRC_(SAE_J1850_CRC-8)
Note:_Details_Please_refer_to_specification《EE_Standard_Specification_for_CAN_FD_Network_Implementation》section_2.3.2";
CM_ SG_ 930 FRM_ACCTarAcc "ACC目标加速度";
CM_ SG_ 930 FRM_VLCShutdownMode "VLC关闭请求";
CM_ SG_ 930 FRM_ACCMode_ESP "The_Status_Of_The_ACC_Control_Unit.
The_ACC_Mode_Should_Be_Contained_In_Every_Message_Sent_By_ACC.";
CM_ SG_ 930 FRM_ComfortAccUpperValue "保证舒适性的加速度上限";
CM_ SG_ 930 FRM_BrakePreferred "制动优先
BrakePreferred_From_ACC_Request_And_Relevant_Request";
CM_ SG_ 930 FRM_ComfortAccLowerValue "保证舒适性的加速度下限";
CM_ SG_ 930 FRM_DriveOff "起步请求
ACC_Request_The_VLC_To_Drive_Off.";
CM_ SG_ 930 FRM_LimitAccUpperValue "目标加速度变化率上限";
CM_ SG_ 930 FRM_DecToStop "制动到停止";
CM_ SG_ 930 FRM_LimitAccLowerValue "目标加速度变化率下限";
CM_ SG_ 930 FRM_ACC_AccECGPOvrd "驾驶员请求扭矩比ACC请求扭矩高
高发0还是1?";
CM_ SG_ 930 FRM_HBALevel "HBA等级
哪三个等级？";
CM_ SG_ 930 FRM_HBARequest "HBA请求";
CM_ SG_ 930 FRM_PrefillRequest "ABP请求";
CM_ SG_ 930 FRM_1_MessageCounter "Rolling_Message_Counter(the_Maximum_Value_Of_Alive_Counter_Is_15)
Note:Details_Please_Refer_To_Specification《Standard_Specification_For_CAN_Data_Link_Layer_V1.1》section_2.3.1";
CM_ SG_ 930 FRM_1_CRC "CRC_(SAE_J1850_CRC-8)
Note:Details_Please_Refer_To_Specification《Standard_Specification_For_CAN_Data_Link_Layer_V1.1》section_2.3.2";
CM_ SG_ 933 FRM_AEBTarDec "AEB目标减速度";
CM_ SG_ 933 FRM_AEBDecCtrlRequest "AEB减速请求";
CM_ SG_ 933 FRM_ACCMinimumBraking "From_ACC_Side_After_Override_ACC_Should_Send_The_Bit_Until_The_Vehcile_Speed_Decease_And_Reach_The_ACC_Set_Speed_In_Order_To_Have_A_Smooth_Brake_
当驾驶员接管后加速超过设定速度，然后驾驶员不再控制车辆后，车辆以最小制动减速到设定车速";
CM_ SG_ 933 FRM_AWBLevel "AWB等级
会根据不同的工况分不同强度点刹提醒驾驶员";
CM_ SG_ 933 FRM_2_MessageCounter "Rolling_Message_Counter(the_Maximum_Value_Of_Alive_Counter_Is_15)
Note:Details_Please_Refer_To_Specification《Standard_Specification_For_CAN_Data_Link_Layer_V1.1》section_2.3.1";
CM_ SG_ 933 FRM_2_CRC "CRC_(SAE_J1850_CRC-8)
Note:Details_Please_Refer_To_Specification《Standard_Specification_For_CAN_Data_Link_Layer_V1.1》section_2.3.2";
CM_ SG_ 1020 FCM_10_LDPTJAELKTakeoverReq "Take_over_request_to_driver";
CM_ SG_ 1020 FCM_10_EgoLeftLineHeatgAg "ICM_display_the_Angle_between_vehicle_and_lane_line";
CM_ SG_ 1020 FCM_10_MsgCntr "Rolling_message_counter(the_maximum_value_of_Alive_counter_is_15)
Note:_Details_Please_refer_to_specification《EE_Standard_Specification_for_CAN_FD_Network_Implementation》section_2.3.1";
CM_ SG_ 1020 FCM_10_CRC "CRC_(SAE_J1850_CRC-8)
Note:_Details_Please_refer_to_specification《EE_Standard_Specification_for_CAN_FD_Network_Implementation》section_2.3.2";
CM_ SG_ 777 LaneCurvatureRadius "车道线曲率半径(左负右正)";
CM_ SG_ 777 FCM_3_ACCLeftObjectDetected "左车道目标状态";
CM_ SG_ 777 FCM_3_ACCRightObjectDetected "右车道目标状态";
CM_ SG_ 777 FCM_3_ACCLeftObject_LatPos "左车道目标横向距离";
CM_ SG_ 777 FCM_3_ACCRightObject_LatPos "右车道目标横向距离";
CM_ SG_ 777 FCM_3_FrontObject_IndicatorRight "前车右转向灯是否点亮";
CM_ SG_ 777 FCM_3_FrontObject_IndicatorLeft "前车右转向灯是否点亮";
CM_ SG_ 777 FCM_3_FrontObject_BrakeLamp "前车刹车灯是否点亮";
CM_ SG_ 777 FCM_3_LeftLane_C0 "本车据左侧车道线距离
（以车辆中心线计算）";
CM_ SG_ 777 FCM_3_RightLane_C0 "本车距右侧车道线距离
（以车辆中心线计算）";
CM_ SG_ 777 FCM_3_NextLeftLane_Mark "左车道左车道线线样式";
CM_ SG_ 777 FCM_3_NextRightLane_Mark "右车道左车道线线样式";
CM_ SG_ 785 FCM_4_LeftLane_Mark "左车道线样式";
CM_ SG_ 785 FCM_4_RightLane_Mark "右车道线样式";
CM_ SG_ 785 FCM_4_LaneLateralPosition_Nextleft "本车据左侧相邻车道的左侧车道线距离
（以车辆中心线计算）";
CM_ SG_ 785 FCM_4_LaneLateralPosition_NextRight "本车据右侧相邻车道的右侧车道线距离
（以车辆中心线计算））";
CM_ SG_ 785 FCM_4_ACCLeftObject_Type "左道目标类型";
CM_ SG_ 785 FCM_4_ACCRightObject_Type "右道目标类型";
CM_ SG_ 785 FCM_4__LatFeature_LeftVisualization "横向功能对左侧车道线介入控制
的状态";
CM_ SG_ 785 FCM_4__LatFeature_RightVisualization "横向功能对右侧车道线介入控制
的状态";
CM_ SG_ 785 FCM_4_ACCLeftObject_LongPos "左车道目标纵向距离";
CM_ SG_ 785 FCM_4_ACCRightObject_LongPos "右车道目标纵向距离";
CM_ SG_ 785 FCM_4_Obiect_Dy "目标横向距离";
CM_ SG_ 250 EMS_1_Checksum "((Byte0+Byte1+Byte3……+Byte7)_AND
0xFF)_XOR_0xFF";
CM_ SG_ 250 EMS_1_GasPedalPosition "Driver/Cruise_Control
This_Signal_Including_Compositive_Informations_Which_Are_Actual_Gas_Pedal_Position_And_Dummy_Cruise_Control_Gas_Pedal_Position
EMS_根据油门踏板传感器获取油门踏板位置，同时发送相应信号值.";
CM_ SG_ 250 EMS_1_AcceleratorPosRaw "Raw_Position_Of_The_Accelerator_Pedal(unfiltered)._Represents_Always_Raw_Pedalposition_Without_Any_Other_Influence_Onlymandatory_To_Calculated_Gradient_Acceleration_Pedal.";
CM_ SG_ 250 EMS_1_MessageCounter "Rolling_Message_Counter";
CM_ SG_ 257 EMS_2_EngineStsForDCT "000:Init_应该是指初始化状态，实际上这个值EMS_发不出来的，CAN_上都已经开始发送信号了，肯定都已经初始化完了。
001:发动机停机状态
010:指起动机正在拖动
011:发动机启动完成
100:因为故障导致跛行";
CM_ SG_ 269 PRNDGearAct "Actual_PRND_Gear_As_Evaluated_By_HCU.";
CM_ SG_ 269 PRNDGearTarget "Target_PRND_Gear_As_Evaluated_By_HCU.";
CM_ SG_ 269 PRNDGearActValidData "Valid_check_bit_of_the_signal__PRNDGearAct";
CM_ SG_ 269 HCU_17_MessageCounter "Alivecounter";
CM_ SG_ 269 HCU_17_CRC "CRC";
CM_ SG_ 295 CGW_YawrateSigValidData "Signal_State_For_Yawrate";
CM_ SG_ 295 CGW_LateralAccelerationSigValidData "If_Hasn’t_Been_Calibrated_After_Initialization_This_Signal_‘s_Value_Is_Always_10(invalid).";
CM_ SG_ 295 CGW_LateralAcceleration "横向加速度信号
传感器精度:0.0027680342857143g";
CM_ SG_ 295 CGW_YawRate "偏航角速度信号
传感器精度:0.122189236_Deg/s";
CM_ SG_ 295 CGW_YAS_1_Checksum "0x01_XOR_0x27_XOR_Byte0_XOR_Byte1_XOR_Byte2_XOR_Byte3_XOR_Byte4_XOR_Byte5_XOR_Byte6";
CM_ SG_ 296 CGW_LongitudinalAccelerationSigValid "If_Hasn’t_Been_Calibrated_After_Initialization_This_Signal_‘s_Value_Is_Always10(invalid)";
CM_ SG_ 296 CGW_LongitudinalAcceleration "纵向加速度信号
传感器精度:0.0027680342857143_G";
CM_ SG_ 296 CGW_YAS_2_Checksum "0x01_XOR_0x28_XOR_Byte0_XOR_Byte1_XOR_Byte2_XOR_Byte3_XOR_Byte4_XOR_Byte5_XOR_Byte6";
CM_ SG_ 647 ICM_5_MessageCounter "国六项目EMS收";
CM_ SG_ 647 ICM_5_Checksum "((Byte0+Byte1+……
+Byte6)_AND_0xFF)_XOR
0xFF";
CM_ SG_ 768 GBPositoionDisplayForPEPS "DCT这个信号为换挡杆物理位置；CVT这个信号，_G中档位显示信号属性可以覆盖此信号。
PEPS:获取P档和N档信号
目标档位
1000—换挡间歇期间，档位符号闪烁，显示上一个档位。
CVT可用到属性里的1-9gear
和PRND。
4AT可用到属性里的1-4gear和PRND
AMT可用到属性里的RND（AMT由手动变速箱更改过来的，没有增加驻车锁，所以没有P档）。
DCT只发出0001、1011、1100、1101、1110、1111
DHT只能发出1011、1100、1101、1110、1111";
CM_ SG_ 768 ActualGear "Gives_The_Actual_Engaged_Gear
实际档位_
DCT无0111_1000两个属性
DHT只能发出1001、1010、1011、1111";
CM_ SG_ 768 DriverMode "CVT有正常、运动、冬季模式；4AT有正常、运动、冬季模式；AMT有正常、经济模式；
DCT有正常、ECO模式，ECO模式通过其他模块给开关信号。";
CM_ SG_ 768 ShiftInProgress "Shift_In_Progress:
shows_If_A_Gear_Shift_Is
actually_In_Progress";
CM_ SG_ 768 TargetGear "The_Gear_That_The_Gearbox_Is_Currently_Changing_To_(this_Is_Valid_When_Gearshift_In_Progress_Equals_1).
Target_Gear是指变速箱将要达到的档位。
Actual_Gear是指变速箱现在实际的档位
DCT无0111_1000两个属性

PHEV的DHT不使用此信号，目标档位由HCU请求";
CM_ SG_ 768 TCU_2_Checksum "((Byte0+Byte1+……+Byte6)_AND_0xFF)_XOR_0xFF";
CM_ SG_ 913 BCM_1_HighBeamSts "HighBeamFlash_Function_Uses
this_Signal.";
CM_ SG_ 913 BCM_1_Checksum "((Byte0+Byte2+……+Byte7)_AND0xFF)_XOR_0xFF";
CM_ SG_ 913 BCM_1_DirectionIndRight "当左/右转向灯闪烁时一直发1，转向灯熄灭时一直发0.";
CM_ SG_ 913 BCM_1_HazardLightSW "危险灯开关，按下（打开）发1；再按下（关闭）发0，默认发0";
CM_ SG_ 913 BCM_1_AutoLightSW "AUTO灯开关，拨到该位置（打开）发1，不拨到该位置（关闭）发0，默认发0";
CM_ SG_ 913 BCM_1_DriverDoorStsQbit "默认由1改为0";
CM_ SG_ 913 BCM_1_HMASW "Intelligent_Headlamp_Control_Switch_From_BCM";
CM_ SG_ 913 BCM_1_AutoHighSpeedRequest "让高速雨刮电机工作";
CM_ SG_ 913 BCM_1_RainDetected "检测到有无雨量";
CM_ SG_ 913 BCM_1_MessageCounter "Rolling_Message_Counter";
CM_ SG_ 1034 HCU_PTReady "Drive_Ready_Indication";
CM_ SG_ 1072 ICM_1_DisplayVehicleSpeed "Reserved";
CM_ SG_ 1072 ICM_1_MessageCounter "Rolling_Message_Counter";
CM_ SG_ 1107 IHU_7_CurrentTimeHour "时";
CM_ SG_ 1107 IHU_7_CurrentTimeMinute "分";
CM_ SG_ 1107 IHU_7_CurrentTimeSecond "秒";
CM_ SG_ 1107 IHU_7_CurrentTimeDay "日";
CM_ SG_ 1107 IHU_7_CurrentTimeMonth "月";
CM_ SG_ 1107 IHU_7_CurrentTimeYear "年";
CM_ SG_ 1282 CDPActive "动态制动时:仪表接收CDPActive=1_Active或RWUActive=1_Active，仪表驻车灯闪烁";
CM_ SG_ 1282 ABS_ESP_MessageCounter "Rolling_Message_Counter(the_Maximum_Value_Of_Alive_Counter_Is_15)
Note:Details_Please_Refer_To_Specification《Standard_Specification_For_CAN_Data_Link_Layer_V1.1》section_2.3.1";
CM_ SG_ 1282 CDPFailSts "建议文字显示，CDP失效";
CM_ SG_ 1282 ABS_ESP_Checksum "((Byte0+Byte1+_Byte2+Byte3+Byte4+Byte5)_AND_0xFF)_XOR_0xFF
Note:Details_Please_Refer_To_Specification《Standard_Specification_For_CAN_Data_Link_Layer_V1.1》section_2.3.3";
CM_ SG_ 1333 CLM_2_MessageCounter "Rolling_Message_Counter";
CM_ SG_ 1333 CLM_2_ExternalTemperatureRaw "Raw_External_Temperature_
Invalid:When_External_Temperature_Is_Fail_The_Signal_Value_Is_0xFF
国六项目EMS接收";
CM_ SG_ 1333 CLM_2_CRCCheck "循环冗余校验
国六项目EMS接收";
CM_ SG_ 1335 IHU_9_NavSpeedLimitStatus "NavSpeedLimitStatus
00:导航不可用
01:有限速
02:无限速
03:有匝道";
CM_ SG_ 1335 IHU_9_NavSpeedLimit "NavSpeedLimit";
CM_ SG_ 1335 IHU_9_NavSpeedLimitUnits "Far/standard/near";
CM_ SG_ 916 EPS_TorsionBarTorque "驾驶员输入方向盘扭矩";
CM_ SG_ 916 EPS_TorsionBarTorqueDir "方向盘扭矩方向";
CM_ SG_ 916 EPS_EpsControlStatus "为LKS对EPS的控制信号";
CM_ SG_ 916 EPS_2_Message_Counter "Rolling_Message_Counter(the_Maximum_Value_Of_Alive_Counter_Is_15)
Note:Details_Please_Refer_To_Specification《Standard_Specification_For_CANFD_Data_Link_Layer_V1.0》section_2.3.1";
CM_ SG_ 916 EPS_2_CRC "CRC_(SAE_J1850_CRC-8)
Note:Details_Please_Refer_To_Specification《Standard_Specification_For_CANFD_Data_Link_Layer_V1.0》section_2.3.2";
CM_ SG_ 1285 EPS_1_EPS_AssistanceStyleSts "0x0:_sport
0x1:_comfort
0x2:_normal";
CM_ SG_ 608 IPB_QDCACC "ACC_Error_Detected_By_ESP_Like_Timeout_Or_Alivecounter_Error.
The_Error_Should_Distinguish_Reversible_And_Irreversible_Errors.";
CM_ SG_ 608 IPB_ABSESP_7_MessageCounter "Rolling_Message_Counter(the_Maximum_Value_Of_Alive_Counter_Is_15)
Note:Details_Please_Refer_To_Specification《Standard_Specification_For_CAN_Data_Link_Layer_V1.1》section_2.3.1";
CM_ SG_ 608 IPB_ABSESP_7_Checksum "((Byte0+Byte1+_Byte2+Byte3+Byte4+Byte5+Byte6)_AND_0xFF)_XOR_0xFF
Note:Details_Please_Refer_To_Specification《Standard_Specification_For_CAN_Data_Link_Layer_V1.1》section_2.3.3";
CM_ SG_ 641 IPB_ABPActive "Automatic_Brake_Pre-fill--自动预制动";
CM_ SG_ 641 IPB_AEBdecActive "AEB_Braking_Function";
CM_ SG_ 641 IPB_ABSESP_8_MessageCounter "Rolling_Message_Counter(the_Maximum_Value_Of_Alive_Counter_Is_15)
Note:Details_Please_Refer_To_Specification《Standard_Specification_For_CAN_Data_Link_Layer_V1.1》section_2.3.1";
CM_ SG_ 641 IPB_ABSESP_8_Checksum "((Byte0+Byte1+_Byte2+Byte3+Byte4+Byte5+Byte6)_AND_0xFF)_XOR_0xFF
Note:Details_Please_Refer_To_Specification《Standard_Specification_For_CAN_Data_Link_Layer_V1.1》section_2.3.3";
CM_ SG_ 666 IPB_InputRodStroke "Indicate_InputRod_Stroke_For_Pedal_Travel";
CM_ SG_ 666 IPB_InputRodStrokeStatus "Indicate_InputRod_Stroke_For_Pedal_Travel";
CM_ SG_ 666 IPB_ESP_11_CRC "(SAE_J1850_CRC-8)";
CM_ SG_ 745 IPB_ABS_ESP_1_VDCActive "ESP_Lamp_On_ICM_Should_Blinking_;VDC_Intervention";
CM_ SG_ 745 IPB_ABS_ESP_1_TCSActive "ESP_Lamp_On_ICM_Should_Blinking;_TCS_Intervention";
CM_ SG_ 745 IPB_ABS_ESP_1_Checksum "((Byte0+Byte1+_Byte2+Byte3+Byte4+Byte6+Byte7)_AND_0xFF)_XOR_0xFF
Note:Details_Please_Refer_To_Specification《Standard_Specification_For_CAN_Data_Link_Layer_V1.1》section_2.3.3";
CM_ SG_ 745 IPB_ABS_ESP_1_MessageCounter "Rolling_Message_Counter(the_Maximum_Value_Of_Alive_Counter_Is_15)
Note:Details_Please_Refer_To_Specification《Standard_Specification_For_CAN_Data_Link_Layer_V1.1》section_2.3.1";
CM_ SG_ 745 IPB_ABS_ESP_1_ESPSwitchStatus "1_Means_VDC_And_Engine_Traction_Control_System_(PTC)_Function_And_Brake_Traction_Control_System_(BTC)_Function_Disabled_And_Ignit_ESP_Lamp.
0x0:ESP功能开启
0x1:ESP功能关闭";
CM_ SG_ 787 IPB_ESP_VLCEngTorqReq "燃烧扭矩
ACC对发动机的扭矩请求";
CM_ SG_ 787 IPB_NoBrakeForce "No_Brake_Pressure_Applied
Generally_It_Regards_Wheel_Cylinder_Pressure
";
CM_ SG_ 787 IPB_ABS_ESP_3_AVHFailSts "AutoHold功能失效状态";
CM_ SG_ 787 IPB_ABS_ESP_3_AVHSts "Auto_Hold功能状态
";
CM_ SG_ 787 IPB_ESP_VLCEngTorqReqValidData "燃烧扭矩
ACC对发动机的扭矩请求";
CM_ SG_ 787 IPB_ABS_ESP_3_MessageCounter "Rolling_Message_Counter(the_Maximum_Value_Of_Alive_Counter_Is_15)
Note:Details_Please_Refer_To_Specification《Standard_Specification_For_CAN_Data_Link_Layer_V1.1》section_2.3.1";
CM_ SG_ 787 IPB_ABS_ESP_3_Checksum "((Byte0+Byte1+_Byte2+Byte3+Byte4+Byte5+Byte6)_AND_0xFF)_XOR_0xFF
Note:Details_Please_Refer_To_Specification《Standard_Specification_For_CAN_Data_Link_Layer_V1.1》section_2.3.3";
CM_ SG_ 790 IPB_VLC_InternalTargetAcceleration "VLC内部加速度";
CM_ SG_ 790 IPB_VehicleStandstill "车辆静止状态";
CM_ SG_ 790 IPB_ECDTempOff "制动盘温度过高";
CM_ SG_ 790 IPB_DCFail "不能执行ACC的减速功能时通知FRM";
CM_ SG_ 790 IPB_VLC_Active "VLC激活";
CM_ SG_ 790 IPB_VLC_Available "VLC可用";
CM_ SG_ 790 IPB_ABS_ESP_4_MessageCounter "Rolling_Message_Counter(the_Maximum_Value_Of_Alive_Counter_Is_15)
Note:Details_Please_Refer_To_Specification《Standard_Specification_For_CAN_Data_Link_Layer_V1.1》section_2.3.1";
CM_ SG_ 790 IPB_ABS_ESP_4_Checksum "((Byte0+Byte1+_Byte2+Byte3+Byte4+Byte5+Byte6)_AND_0xFF)_XOR_0xFF
Note:Details_Please_Refer_To_Specification《Standard_Specification_For_CAN_Data_Link_Layer_V1.1》section_2.3.3";
CM_ SG_ 1270 IPB_EPBErrorStatus "用于EPB故障显示
夹紧力不够时也发Error
";
CM_ SG_ 1270 IPB_EPBStatus "卡钳处于释放状态
卡钳处于夹紧状态
卡钳正处于释放过程中
卡钳正处于夹紧过程中
未知状态:当前卡钳处于未知状态
ErrorApplied:
当EPBError之前卡钳已经处于夹紧状态_用户再操作EPB(apply)开关时发101进行闪烁报警；
当EPBError之后卡钳处于夹紧状态_发101进行闪烁报警。
0x0:Released（电子驻车已释放）ICM做策略，只提示5s
0x1:Applied（电子驻车已启用）ICM做策略，只提示5s
0x2:Releasing
0x3:Applying
0x4:Unknown
0x5:ErrorApplied（公共CAN无此信号，会发0x4_unknown）
0x6:Not_Used
0x7:Not_Used";
BA_DEF_ "DBName" STRING;
BA_DEF_ "BusType" STRING;
BA_DEF_ "NmMessageCount" INT 0 255;
BA_DEF_ "NmBaseAddress" HEX 1024 536870911;
BA_DEF_ BO_ "GenMsgCycleTimeFast" INT 0 50000;
BA_DEF_ BO_ "GenMsgNrOfRepetition" INT 0 999999;
BA_DEF_ BO_ "VFrameFormat" ENUM  "StandardCAN", "ExtendedCAN", "reserved", "reserved", "reserved", "reserved", "reserved", "reserved", "reserved", "reserved", "reserved", "reserved", "reserved", "reserved", "StandardCAN_FD", "ExtendedCAN_FD";
BA_DEF_ BO_ "GenMsgILSupport" ENUM  "No", "Yes";
BA_DEF_ BO_ "NmMessage" ENUM  "no", "yes";
BA_DEF_ BO_ "DiagMessage" ENUM  "no", "yes";
BA_DEF_ BO_ "GenMsgSendType" ENUM  "Cycle", "Event", "IfActive", "CE", "CA", "NoMsgSendType";
BA_DEF_ BO_ "GenMsgCycleTime" INT 0 50000;
BA_DEF_ SG_ "GenSigSendType" ENUM  "Cycle", "OnChange", "OnWrite", "IfActive", "OnChangeWithRepetition", "OnWriteWithRepetition", "IfActiveWithRepetition", "NoSigSendType", "OnChangeAndIfActive", "OnChangeAndIfActiveWithRepetition", "CA", "CE", "Event";
BA_DEF_ SG_ "GenSigStartValue" FLOAT 0 100000000000;
BA_DEF_ SG_ "GenSigInvalidValue" INT 0 100000;
BA_DEF_DEF_ "BusType" "CAN FD";
BA_DEF_DEF_ "NmMessageCount" 128;
BA_DEF_DEF_ "NmBaseAddress" 1024;
BA_DEF_DEF_ "GenMsgCycleTimeFast" 0;
BA_DEF_DEF_ "GenMsgNrOfRepetition" 0;
BA_DEF_DEF_ "VFrameFormat" "StandardCAN";
BA_DEF_DEF_ "GenMsgILSupport" "No";
BA_DEF_DEF_ "NmMessage" "no";
BA_DEF_DEF_ "DiagMessage" "no";
BA_DEF_DEF_ "GenMsgSendType" "NoMsgSendType";
BA_DEF_DEF_ "GenMsgCycleTime" 0;
BA_DEF_DEF_ "GenSigSendType" "NoSigSendType";
BA_DEF_DEF_ "GenSigStartValue" 0;
BA_ "DBName" "T1JPHEV电四驱底盘1CNAFD-FCM配置_FCM";
BA_ "VFrameFormat" BO_ 773 14;
BA_ "GenMsgILSupport" BO_ 773 1;
BA_ "GenMsgSendType" BO_ 773 0;
BA_ "GenMsgCycleTime" BO_ 773 50;
BA_ "GenSigSendType" SG_ 773 FRM_3_VSetDis 0;
BA_ "GenSigSendType" SG_ 773 FRM_3_DxTarObj 0;
BA_ "GenSigSendType" SG_ 773 FRM_3_ObjValid 0;
BA_ "GenSigSendType" SG_ 773 FRM_3_FrontObject_Type 0;
BA_ "GenSigSendType" SG_ 773 FRM_3_Textinfo 0;
BA_ "GenSigSendType" SG_ 773 FRM_3_TakeOverReq 0;
BA_ "GenSigSendType" SG_ 773 FRM_3_TimeGapSet_ICM 0;
BA_ "GenSigSendType" SG_ 773 FRM_3_ACCMode 0;
BA_ "GenSigSendType" SG_ 773 FRM_3_Obiect_Dx 0;
BA_ "GenSigSendType" SG_ 773 FRM_3_FCWMode 0;
BA_ "GenSigSendType" SG_ 773 FRM_3_AEBMode 0;
BA_ "GenSigSendType" SG_ 773 FRM_3_DistanceWarning 0;
BA_ "GenSigSendType" SG_ 773 FRM_3_FCW_PreWarning 0;
BA_ "GenSigSendType" SG_ 773 FRM_3_FCW_ON_OFF_Sts 0;
BA_ "GenSigSendType" SG_ 773 FRM_3_FCW_OPTION_Sts 0;
BA_ "GenSigSendType" SG_ 773 FRM_3_AEB_ON_OFF_Sts 0;
BA_ "GenSigSendType" SG_ 773 FRM_3_MessageCounter 0;
BA_ "GenSigSendType" SG_ 773 FRM_3_CRC 0;
BA_ "VFrameFormat" BO_ 775 14;
BA_ "GenMsgILSupport" BO_ 775 1;
BA_ "GenMsgSendType" BO_ 775 0;
BA_ "GenMsgCycleTime" BO_ 775 50;
BA_ "GenSigSendType" SG_ 775 FCM_2_HMA_Status 0;
BA_ "GenSigStartValue" SG_ 775 FCM_2_HMA_Status 1;
BA_ "GenSigSendType" SG_ 775 FCM_2_HMA_HighbeamReq 0;
BA_ "GenSigSendType" SG_ 775 FCM_2_HMAOnOffsts 0;
BA_ "GenSigSendType" SG_ 775 FCM_2_LDW_LKA_LeftVisualization 0;
BA_ "GenSigSendType" SG_ 775 FCM_2_LDW_LKA_RightVisualization 0;
BA_ "GenSigSendType" SG_ 775 FCM_2_TrailorModeSts 0;
BA_ "GenSigSendType" SG_ 775 FCM_2_LDP_Status 0;
BA_ "GenSigSendType" SG_ 775 FCM_2_LDWLKA_Sensitivityfeedback 0;
BA_ "GenSigSendType" SG_ 775 FCM_2_SLAState 0;
BA_ "GenSigStartValue" SG_ 775 FCM_2_SLAState 1;
BA_ "GenSigSendType" SG_ 775 FCM_2_SLASpdlimit 0;
BA_ "GenSigSendType" SG_ 775 FCM_2_SLAOnOffsts 0;
BA_ "GenSigSendType" SG_ 775 FCM_2_SLASpdlimitWarning 0;
BA_ "GenSigSendType" SG_ 775 FCM_2_Camera_Textinfo 0;
BA_ "GenSigSendType" SG_ 775 FCM_2_ADAS_TakeoverReq 0;
BA_ "GenSigSendType" SG_ 775 FCM_2_TJA_ICA_Textinfo 0;
BA_ "GenSigSendType" SG_ 775 FCM_2_TJA_ICA_Mode 0;
BA_ "GenSigSendType" SG_ 775 FCM_2_LDWOnOffSts 0;
BA_ "GenSigSendType" SG_ 775 FCM_2_MessageCounter 0;
BA_ "GenSigSendType" SG_ 775 FCM_2_weather_signal 0;
BA_ "GenSigSendType" SG_ 775 FCM_2_CRCCheck 0;
BA_ "VFrameFormat" BO_ 809 14;
BA_ "GenMsgILSupport" BO_ 809 1;
BA_ "GenMsgSendType" BO_ 809 0;
BA_ "GenMsgCycleTime" BO_ 809 50;
BA_ "GenSigSendType" SG_ 809 LDW_Status 0;
BA_ "GenSigSendType" SG_ 809 LDPSwitchFeedback 0;
BA_ "GenSigSendType" SG_ 809 IESSwtSetFeedback 0;
BA_ "GenSigSendType" SG_ 809 TJA_ICA_WarmingSwitchFeedback 0;
BA_ "VFrameFormat" BO_ 837 14;
BA_ "GenMsgILSupport" BO_ 837 1;
BA_ "GenMsgSendType" BO_ 837 0;
BA_ "GenMsgCycleTime" BO_ 837 20;
BA_ "GenSigSendType" SG_ 837 FCM_3_HptcVibReq 0;
BA_ "GenSigSendType" SG_ 837 FCM_3_StrngWhlAgReqActive 0;
BA_ "GenSigSendType" SG_ 837 FCM_3_StrngWhlAgReq 0;
BA_ "GenSigStartValue" SG_ 837 FCM_3_StrngWhlAgReq 15610;
BA_ "GenSigSendType" SG_ 837 FCM_3_MsgCntr 0;
BA_ "GenSigSendType" SG_ 837 FCM_3_CRC 0;
BA_ "GenSigSendType" SG_ 837 Read2go_Active 0;
BA_ "GenSigSendType" SG_ 837 Read2go_On_Off_FEEDBACK 0;
BA_ "VFrameFormat" BO_ 930 14;
BA_ "GenMsgILSupport" BO_ 930 1;
BA_ "GenMsgSendType" BO_ 930 0;
BA_ "GenMsgCycleTime" BO_ 930 20;
BA_ "GenSigSendType" SG_ 930 FRM_ACCTarAcc 0;
BA_ "GenSigSendType" SG_ 930 FRM_VLCShutdownMode 0;
BA_ "GenSigStartValue" SG_ 930 FRM_VLCShutdownMode 3;
BA_ "GenSigSendType" SG_ 930 FRM_ACCMode_ESP 0;
BA_ "GenSigSendType" SG_ 930 FRM_ComfortAccUpperValue 0;
BA_ "GenSigSendType" SG_ 930 FRM_BrakePreferred 0;
BA_ "GenSigSendType" SG_ 930 FRM_ComfortAccLowerValue 0;
BA_ "GenSigSendType" SG_ 930 FRM_DriveOff 0;
BA_ "GenSigSendType" SG_ 930 FRM_LimitAccUpperValue 0;
BA_ "GenSigSendType" SG_ 930 FRM_DecToStop 0;
BA_ "GenSigSendType" SG_ 930 FRM_LimitAccLowerValue 0;
BA_ "GenSigSendType" SG_ 930 FRM_ACC_AccECGPOvrd 0;
BA_ "GenSigSendType" SG_ 930 FRM_HBALevel 0;
BA_ "GenSigSendType" SG_ 930 FRM_HBARequest 0;
BA_ "GenSigSendType" SG_ 930 FRM_PrefillRequest 0;
BA_ "GenSigSendType" SG_ 930 FRM_1_MessageCounter 0;
BA_ "GenSigSendType" SG_ 930 FRM_1_CRC 0;
BA_ "VFrameFormat" BO_ 933 14;
BA_ "GenMsgILSupport" BO_ 933 1;
BA_ "GenMsgSendType" BO_ 933 0;
BA_ "GenMsgCycleTime" BO_ 933 20;
BA_ "GenSigSendType" SG_ 933 FRM_AEBTarDec 0;
BA_ "GenSigStartValue" SG_ 933 FRM_AEBTarDec 32773.453502662843097091356002;
BA_ "GenSigSendType" SG_ 933 FRM_AEBDecCtrlRequest 0;
BA_ "GenSigSendType" SG_ 933 FRM_ACCMinimumBraking 0;
BA_ "GenSigSendType" SG_ 933 FRM_2_ACCStartStopInfo 0;
BA_ "GenSigSendType" SG_ 933 FRM_AWBRequest 0;
BA_ "GenSigSendType" SG_ 933 FRM_AWBLevel 0;
BA_ "GenSigSendType" SG_ 933 FRM_2_MessageCounter 0;
BA_ "GenSigSendType" SG_ 933 FRM_2_CRC 0;
BA_ "VFrameFormat" BO_ 1020 14;
BA_ "GenMsgILSupport" BO_ 1020 1;
BA_ "GenMsgSendType" BO_ 1020 0;
BA_ "GenMsgCycleTime" BO_ 1020 50;
BA_ "GenSigSendType" SG_ 1020 FCM_10_LDPTJAELKTakeoverReq 0;
BA_ "GenSigSendType" SG_ 1020 FCM_10_EgoLeftLineHeatgAg 0;
BA_ "GenSigStartValue" SG_ 1020 FCM_10_EgoLeftLineHeatgAg 255;
BA_ "GenSigInvalidValue" SG_ 1020 FCM_10_EgoLeftLineHeatgAg 511;
BA_ "GenSigSendType" SG_ 1020 FCM_10_MsgCntr 0;
BA_ "GenSigSendType" SG_ 1020 FCM_10_CRC 0;
BA_ "VFrameFormat" BO_ 777 14;
BA_ "GenMsgILSupport" BO_ 777 1;
BA_ "GenMsgSendType" BO_ 777 0;
BA_ "GenMsgCycleTime" BO_ 777 100;
BA_ "GenSigSendType" SG_ 777 LaneCurvatureRadius 0;
BA_ "GenSigSendType" SG_ 777 FCM_3_ACCLeftObjectDetected 0;
BA_ "GenSigSendType" SG_ 777 FCM_3_ACCRightObjectDetected 0;
BA_ "GenSigSendType" SG_ 777 FCM_3_ACCLeftObject_LatPos 0;
BA_ "GenSigSendType" SG_ 777 FCM_3_ACCRightObject_LatPos 0;
BA_ "GenSigSendType" SG_ 777 FCM_3_FrontObject_IndicatorRight 0;
BA_ "GenSigSendType" SG_ 777 FCM_3_FrontObject_IndicatorLeft 0;
BA_ "GenSigSendType" SG_ 777 FCM_3_FrontObject_BrakeLamp 0;
BA_ "GenSigSendType" SG_ 777 FCM_3_LeftLane_C0 0;
BA_ "GenSigSendType" SG_ 777 FCM_3_RightLane_C0 0;
BA_ "GenSigSendType" SG_ 777 FCM_3_NoLeftTurn_sign 0;
BA_ "GenSigSendType" SG_ 777 FCM_3_NoRightTurn_sign 0;
BA_ "GenSigSendType" SG_ 777 FCM_3_StopSign 0;
BA_ "GenSigSendType" SG_ 777 FCM_3_NOU_turnsign 0;
BA_ "GenSigSendType" SG_ 777 FCM_3_Noentrysign 0;
BA_ "GenSigSendType" SG_ 777 FCM_3_Constructionareasign 0;
BA_ "GenSigSendType" SG_ 777 FCM_3_Crossingsign 0;
BA_ "GenSigSendType" SG_ 777 FCM_3_YieldSIgn 0;
BA_ "GenSigSendType" SG_ 777 FCM_3_NextLeftLane_Mark 0;
BA_ "GenSigSendType" SG_ 777 FCM_3_NextRightLane_Mark 0;
BA_ "VFrameFormat" BO_ 785 14;
BA_ "GenMsgILSupport" BO_ 785 1;
BA_ "GenMsgSendType" BO_ 785 0;
BA_ "GenMsgCycleTime" BO_ 785 100;
BA_ "GenSigSendType" SG_ 785 FCM_4_LeftLane_Mark 0;
BA_ "GenSigSendType" SG_ 785 FCM_4_RightLane_Mark 0;
BA_ "GenSigSendType" SG_ 785 FCM_4_LaneLateralPosition_Nextleft 0;
BA_ "GenSigSendType" SG_ 785 FCM_4_LaneLateralPosition_NextRight 0;
BA_ "GenSigSendType" SG_ 785 FCM_4_ACCLeftObject_Type 0;
BA_ "GenSigSendType" SG_ 785 FCM_4_ACCRightObject_Type 0;
BA_ "GenSigSendType" SG_ 785 FCM_4__LatFeature_LeftVisualization 0;
BA_ "GenSigSendType" SG_ 785 FCM_4__LatFeature_RightVisualization 0;
BA_ "GenSigSendType" SG_ 785 FCM_4_ACCLeftObject_LongPos 0;
BA_ "GenSigSendType" SG_ 785 FCM_4_ACCRightObject_LongPos 0;
BA_ "GenSigSendType" SG_ 785 FCM_4_Obiect_Dy 0;
BA_ "VFrameFormat" BO_ 196 14;
BA_ "GenMsgILSupport" BO_ 196 1;
BA_ "GenMsgSendType" BO_ 196 0;
BA_ "GenMsgCycleTime" BO_ 196 10;
BA_ "GenSigSendType" SG_ 196 SAS_1_SteeringAngle 0;
BA_ "GenSigSendType" SG_ 196 SAS_1_SteeringAngleSpeed 0;
BA_ "GenSigSendType" SG_ 196 SAS_1_AngleFailure 0;
BA_ "GenSigSendType" SG_ 196 SAS_1_SASCalibrated 0;
BA_ "GenSigSendType" SG_ 196 SAS_1_SteeringAngleValidData 0;
BA_ "GenSigSendType" SG_ 196 SAS_1_SteeringAngleSpeedValidData 0;
BA_ "GenSigSendType" SG_ 196 SAS_1_MessageCounter 0;
BA_ "GenSigSendType" SG_ 196 SAS_1_CRCCheck 0;
BA_ "VFrameFormat" BO_ 250 14;
BA_ "GenMsgILSupport" BO_ 250 1;
BA_ "GenMsgSendType" BO_ 250 0;
BA_ "GenMsgCycleTime" BO_ 250 10;
BA_ "GenSigSendType" SG_ 250 EMS_1_EngineSpeed 0;
BA_ "GenSigInvalidValue" SG_ 250 EMS_1_EngineSpeed 65535;
BA_ "GenSigSendType" SG_ 250 EMS_1_Checksum 0;
BA_ "GenSigSendType" SG_ 250 EMS_1_GasPedalPosition 0;
BA_ "GenSigSendType" SG_ 250 EMS_1_GasPedalPositionInvalidData 0;
BA_ "GenSigSendType" SG_ 250 EMS_1_AcceleratorPosRaw 0;
BA_ "GenSigInvalidValue" SG_ 250 EMS_1_AcceleratorPosRaw 255;
BA_ "GenSigSendType" SG_ 250 EMS_1_ECFail 0;
BA_ "GenSigSendType" SG_ 250 EMS_1_ECGPOvrd 0;
BA_ "GenSigSendType" SG_ 250 EMS_1_MessageCounter 0;
BA_ "VFrameFormat" BO_ 257 14;
BA_ "GenMsgILSupport" BO_ 257 1;
BA_ "GenMsgSendType" BO_ 257 0;
BA_ "GenMsgCycleTime" BO_ 257 10;
BA_ "GenSigSendType" SG_ 257 EMS_2_BrakePedalStsValidDataForTCU 0;
BA_ "GenSigSendType" SG_ 257 EMS_2_BrakePedalStsForTCU 0;
BA_ "GenSigSendType" SG_ 257 EMS_2_EngineStsForDCT 0;
BA_ "GenSigInvalidValue" SG_ 257 EMS_2_EngineStsForDCT 7;
BA_ "VFrameFormat" BO_ 269 14;
BA_ "GenMsgILSupport" BO_ 269 1;
BA_ "GenMsgSendType" BO_ 269 0;
BA_ "GenMsgCycleTime" BO_ 269 10;
BA_ "GenSigSendType" SG_ 269 PRNDGearAct 0;
BA_ "GenSigSendType" SG_ 269 PRNDGearTarget 0;
BA_ "GenSigSendType" SG_ 269 PRNDGearActValidData 0;
BA_ "GenSigSendType" SG_ 269 HCU_17_MessageCounter 0;
BA_ "GenSigSendType" SG_ 269 HCU_17_CRC 0;
BA_ "VFrameFormat" BO_ 295 14;
BA_ "GenMsgILSupport" BO_ 295 1;
BA_ "GenMsgSendType" BO_ 295 0;
BA_ "GenMsgCycleTime" BO_ 295 20;
BA_ "GenSigSendType" SG_ 295 CGW_YAS_1_MessageCounter 0;
BA_ "GenSigSendType" SG_ 295 CGW_YawrateSigValidData 0;
BA_ "GenSigStartValue" SG_ 295 CGW_YawrateSigValidData 3;
BA_ "GenSigSendType" SG_ 295 CGW_LateralAccelerationSigValidData 0;
BA_ "GenSigStartValue" SG_ 295 CGW_LateralAccelerationSigValidData 3;
BA_ "GenSigSendType" SG_ 295 CGW_LateralAcceleration 0;
BA_ "GenSigStartValue" SG_ 295 CGW_LateralAcceleration 2000;
BA_ "GenSigInvalidValue" SG_ 295 CGW_LateralAcceleration 65535;
BA_ "GenSigSendType" SG_ 295 CGW_YawRate 0;
BA_ "GenSigStartValue" SG_ 295 CGW_YawRate 18000;
BA_ "GenSigInvalidValue" SG_ 295 CGW_YawRate 65535;
BA_ "GenSigSendType" SG_ 295 CGW_YAS_1_Checksum 0;
BA_ "VFrameFormat" BO_ 296 14;
BA_ "GenMsgILSupport" BO_ 296 1;
BA_ "GenMsgSendType" BO_ 296 0;
BA_ "GenMsgCycleTime" BO_ 296 20;
BA_ "GenSigSendType" SG_ 296 CGW_YAS_2_MessageCounter 0;
BA_ "GenSigSendType" SG_ 296 CGW_LongitudinalAccelerationSigValid 0;
BA_ "GenSigStartValue" SG_ 296 CGW_LongitudinalAccelerationSigValid 3;
BA_ "GenSigSendType" SG_ 296 CGW_LongitudinalAcceleration 0;
BA_ "GenSigStartValue" SG_ 296 CGW_LongitudinalAcceleration 2000;
BA_ "GenSigInvalidValue" SG_ 296 CGW_LongitudinalAcceleration 65535;
BA_ "GenSigSendType" SG_ 296 CGW_YAS_2_Checksum 0;
BA_ "VFrameFormat" BO_ 647 14;
BA_ "GenMsgILSupport" BO_ 647 1;
BA_ "GenMsgSendType" BO_ 647 0;
BA_ "GenMsgCycleTime" BO_ 647 20;
BA_ "GenSigSendType" SG_ 647 ICM_5_DriverSeatBeltSwitch 0;
BA_ "GenSigSendType" SG_ 647 ICM_5_DriverSeatBeltSwitchQbit 0;
BA_ "GenSigSendType" SG_ 647 ICM_5_ACC_Kilometre_Mile 0;
BA_ "GenSigSendType" SG_ 647 ICM_5_MessageCounter 0;
BA_ "GenSigSendType" SG_ 647 ICM_5_Checksum 0;
BA_ "VFrameFormat" BO_ 768 14;
BA_ "GenMsgILSupport" BO_ 768 1;
BA_ "GenMsgSendType" BO_ 768 0;
BA_ "GenMsgCycleTime" BO_ 768 10;
BA_ "GenSigSendType" SG_ 768 GBPositoionDisplayForPEPS 0;
BA_ "GenSigStartValue" SG_ 768 GBPositoionDisplayForPEPS 15;
BA_ "GenSigInvalidValue" SG_ 768 GBPositoionDisplayForPEPS 15;
BA_ "GenSigSendType" SG_ 768 ActualGear 0;
BA_ "GenSigStartValue" SG_ 768 ActualGear 15;
BA_ "GenSigInvalidValue" SG_ 768 ActualGear 15;
BA_ "GenSigSendType" SG_ 768 DriverMode 0;
BA_ "GenSigSendType" SG_ 768 TargetGearValidData 0;
BA_ "GenSigSendType" SG_ 768 ActualGearValidData 0;
BA_ "GenSigSendType" SG_ 768 ShiftInProgress 0;
BA_ "GenSigSendType" SG_ 768 ShiftInProgressValidData 0;
BA_ "GenSigSendType" SG_ 768 TargetGear 0;
BA_ "GenSigStartValue" SG_ 768 TargetGear 15;
BA_ "GenSigInvalidValue" SG_ 768 TargetGear 15;
BA_ "GenSigSendType" SG_ 768 TCU_2_MessageCounter 0;
BA_ "GenSigSendType" SG_ 768 TCU_2_Checksum 0;
BA_ "VFrameFormat" BO_ 864 14;
BA_ "GenMsgILSupport" BO_ 864 1;
BA_ "GenMsgSendType" BO_ 864 1;
BA_ "GenSigSendType" SG_ 864 CRC 5;
BA_ "GenSigSendType" SG_ 864 ALIVE_MFS_2 5;
BA_ "GenSigSendType" SG_ 864 MFS_Cruise_Control 5;
BA_ "GenSigSendType" SG_ 864 MFS_Seepd_Limit 5;
BA_ "GenSigSendType" SG_ 864 MFS_Cancel 5;
BA_ "GenSigSendType" SG_ 864 MFS_RESPlus 5;
BA_ "GenSigSendType" SG_ 864 MFS_SETMinus 5;
BA_ "GenSigSendType" SG_ 864 MFS_Time_Gap 5;
BA_ "GenSigSendType" SG_ 864 MFS_Time_Gap_Add 5;
BA_ "GenSigSendType" SG_ 864 MFS_Time_Gap_Reduce 5;
BA_ "VFrameFormat" BO_ 913 14;
BA_ "GenMsgILSupport" BO_ 913 1;
BA_ "GenMsgSendType" BO_ 913 0;
BA_ "GenMsgCycleTime" BO_ 913 20;
BA_ "GenSigSendType" SG_ 913 BCM_1_HighBeamSts 0;
BA_ "GenSigSendType" SG_ 913 BCM_1_LowBeamSts 0;
BA_ "GenSigSendType" SG_ 913 BCM_1_KeySts 0;
BA_ "GenSigSendType" SG_ 913 BCM_1_Checksum 0;
BA_ "GenSigSendType" SG_ 913 BCM_1_DirectionIndRight 0;
BA_ "GenSigSendType" SG_ 913 BCM_1_DirectionIndLeft 0;
BA_ "GenSigSendType" SG_ 913 BCM_1_HazardLightSW 0;
BA_ "GenSigSendType" SG_ 913 BCM_1_AutoLightSW 0;
BA_ "GenSigSendType" SG_ 913 BCM_1_DriverDoorSts 0;
BA_ "GenSigSendType" SG_ 913 BCM_1_PsngrDoorSts 0;
BA_ "GenSigSendType" SG_ 913 BCM_1_HoodSts 0;
BA_ "GenSigSendType" SG_ 913 BCM_1_RHRDoorSts 0;
BA_ "GenSigSendType" SG_ 913 BCM_1_LHRdoorSts 0;
BA_ "GenSigSendType" SG_ 913 BCM_1_TrunkSts 0;
BA_ "GenSigSendType" SG_ 913 BCM_1_DriverDoorStsQbit 0;
BA_ "GenSigSendType" SG_ 913 BCM_1_HMASW 0;
BA_ "GenSigSendType" SG_ 913 BCM_1_FrontFogLightSts 0;
BA_ "GenSigSendType" SG_ 913 BCM_1_HighBeamSWSts 0;
BA_ "GenSigSendType" SG_ 913 BCM_1_FlashSWSts 0;
BA_ "GenSigSendType" SG_ 913 BCM_1_WiperSts 0;
BA_ "GenSigSendType" SG_ 913 BCM_1_AutoHighSpeedRequest 0;
BA_ "GenSigSendType" SG_ 913 BCM_1_RainDetected 0;
BA_ "GenSigSendType" SG_ 913 BCM_1_MessageCounter 0;
BA_ "VFrameFormat" BO_ 1034 14;
BA_ "GenMsgILSupport" BO_ 1034 1;
BA_ "GenMsgSendType" BO_ 1034 0;
BA_ "GenMsgCycleTime" BO_ 1034 100;
BA_ "GenSigSendType" SG_ 1034 HCU_PTReady 0;
BA_ "VFrameFormat" BO_ 1072 14;
BA_ "GenMsgILSupport" BO_ 1072 1;
BA_ "GenMsgSendType" BO_ 1072 0;
BA_ "GenMsgCycleTime" BO_ 1072 20;
BA_ "GenSigSendType" SG_ 1072 ICM_1_DisplayVehicleSpeed 0;
BA_ "GenSigSendType" SG_ 1072 ICM_1_MessageCounter 0;
BA_ "GenSigSendType" SG_ 1072 ICM_1_TotalOdometer_Km 0;
BA_ "VFrameFormat" BO_ 1107 14;
BA_ "GenMsgILSupport" BO_ 1107 1;
BA_ "GenMsgSendType" BO_ 1107 0;
BA_ "GenMsgCycleTime" BO_ 1107 500;
BA_ "GenSigSendType" SG_ 1107 IHU_7_CurrentTimeHour 0;
BA_ "GenSigSendType" SG_ 1107 IHU_7_CurrentTimeMinute 0;
BA_ "GenSigSendType" SG_ 1107 IHU_7_CurrentTimeSecond 0;
BA_ "GenSigSendType" SG_ 1107 IHU_7_CurrentTimeDay 0;
BA_ "GenSigSendType" SG_ 1107 IHU_7_CurrentTimeMonth 0;
BA_ "GenSigStartValue" SG_ 1107 IHU_7_CurrentTimeMonth 1;
BA_ "GenSigSendType" SG_ 1107 IHU_7_CurrentTimeYear 0;
BA_ "VFrameFormat" BO_ 1282 14;
BA_ "GenMsgILSupport" BO_ 1282 1;
BA_ "GenMsgSendType" BO_ 1282 0;
BA_ "GenMsgCycleTime" BO_ 1282 100;
BA_ "GenSigSendType" SG_ 1282 CDPActive 0;
BA_ "GenSigSendType" SG_ 1282 ABS_ESP_MessageCounter 0;
BA_ "GenSigSendType" SG_ 1282 CDPFailSts 0;
BA_ "GenSigSendType" SG_ 1282 ABS_ESP_Checksum 0;
BA_ "VFrameFormat" BO_ 1333 14;
BA_ "GenMsgILSupport" BO_ 1333 1;
BA_ "GenMsgSendType" BO_ 1333 0;
BA_ "GenMsgCycleTime" BO_ 1333 100;
BA_ "GenSigSendType" SG_ 1333 CLM_2_MessageCounter 0;
BA_ "GenSigSendType" SG_ 1333 CLM_2_ExternalTemperatureFailSts_GS 0;
BA_ "GenSigSendType" SG_ 1333 CLM_2_ExternalTemperatureRaw 0;
BA_ "GenSigStartValue" SG_ 1333 CLM_2_ExternalTemperatureRaw 80;
BA_ "GenSigSendType" SG_ 1333 CLM_2_CRCCheck 0;
BA_ "VFrameFormat" BO_ 1335 14;
BA_ "GenMsgILSupport" BO_ 1335 1;
BA_ "GenMsgSendType" BO_ 1335 0;
BA_ "GenMsgCycleTime" BO_ 1335 100;
BA_ "GenSigSendType" SG_ 1335 IHU_9_NavSpeedLimitStatus 0;
BA_ "GenSigSendType" SG_ 1335 IHU_9_NavSpeedLimit 0;
BA_ "GenSigSendType" SG_ 1335 IHU_9_NavSpeedLimitUnits 0;
BA_ "GenSigSendType" SG_ 1335 IHU_DriveMode 0;
BA_ "GenSigSendType" SG_ 1335 IHU_9_NavCurrRoadType 0;
BA_ "GenMsgCycleTimeFast" BO_ 1276 100;
BA_ "GenMsgNrOfRepetition" BO_ 1276 3;
BA_ "VFrameFormat" BO_ 1276 14;
BA_ "GenMsgILSupport" BO_ 1276 1;
BA_ "GenMsgSendType" BO_ 1276 1;
BA_ "GenSigSendType" SG_ 1276 IHU_11_AEBSwtSet 5;
BA_ "GenSigSendType" SG_ 1276 IHU_11_FCWSnvtySet 5;
BA_ "GenSigSendType" SG_ 1276 IHU_11_FCWSwtSet 5;
BA_ "GenSigSendType" SG_ 1276 IHU_11_TJAICAExitTextInfoSwtSet 5;
BA_ "GenSigSendType" SG_ 1276 IHU_11_SLASwtSet 5;
BA_ "GenSigSendType" SG_ 1276 IHU_11_SCFSwtSet 5;
BA_ "GenSigSendType" SG_ 1276 IHU_11_DAISwtSet 5;
BA_ "GenSigSendType" SG_ 1276 IHU_11_IESSwtSet 5;
BA_ "GenSigSendType" SG_ 1276 IHU_11_HMASwtSet 5;
BA_ "GenSigSendType" SG_ 1276 IHU_11_LDWSwtSet 5;
BA_ "GenSigSendType" SG_ 1276 IHU_11_LDPSwtSet 5;
BA_ "GenSigSendType" SG_ 1276 IHU_11_LDWLDPSnvtySet 5;
BA_ "VFrameFormat" BO_ 932 14;
BA_ "GenMsgILSupport" BO_ 932 1;
BA_ "GenMsgSendType" BO_ 932 0;
BA_ "GenMsgCycleTime" BO_ 932 20;
BA_ "GenSigSendType" SG_ 932 ESP_18_CCO_Active 0;
BA_ "GenMsgILSupport" BO_ 1487 1;
BA_ "GenMsgSendType" BO_ 1487 0;
BA_ "GenMsgCycleTime" BO_ 1487 500;
BA_ "GenSigSendType" SG_ 1487 TRM_1_MotorHomeConnectSts 0;
BA_ "GenSigSendType" SG_ 1487 TRM_1_RollingCounter 0;
BA_ "VFrameFormat" BO_ 916 14;
BA_ "GenMsgILSupport" BO_ 916 1;
BA_ "GenMsgSendType" BO_ 916 0;
BA_ "GenMsgCycleTime" BO_ 916 20;
BA_ "GenSigSendType" SG_ 916 EPS_TorsionBarTorque 0;
BA_ "GenSigSendType" SG_ 916 EPS_TorsionBarTorqueDir 0;
BA_ "GenSigSendType" SG_ 916 EPS_TosionBarTorqueValid 0;
BA_ "GenSigSendType" SG_ 916 EPS_EpsControlStatus 0;
BA_ "GenSigSendType" SG_ 916 EPS_2_Message_Counter 0;
BA_ "GenSigSendType" SG_ 916 EPS_2_CRC 0;
BA_ "VFrameFormat" BO_ 1285 14;
BA_ "GenMsgILSupport" BO_ 1285 1;
BA_ "GenMsgSendType" BO_ 1285 0;
BA_ "GenMsgCycleTime" BO_ 1285 100;
BA_ "GenSigSendType" SG_ 1285 EPS_1_EPS_AssistanceStyleSts 0;
BA_ "VFrameFormat" BO_ 467 14;
BA_ "GenMsgILSupport" BO_ 467 1;
BA_ "GenMsgSendType" BO_ 467 0;
BA_ "GenMsgCycleTime" BO_ 467 10;
BA_ "GenSigSendType" SG_ 467 EPS_3_StrngWhlAgValid 0;
BA_ "GenSigSendType" SG_ 467 EPS_3_StrngWhlAg 0;
BA_ "GenSigSendType" SG_ 467 EPS_3_AgFailr 0;
BA_ "GenSigSendType" SG_ 467 EPS_3_Message_Counter 0;
BA_ "GenSigSendType" SG_ 467 EPS_3_CRC 0;
BA_ "VFrameFormat" BO_ 483 14;
BA_ "GenMsgILSupport" BO_ 483 1;
BA_ "GenMsgSendType" BO_ 483 0;
BA_ "GenMsgCycleTime" BO_ 483 10;
BA_ "GenSigSendType" SG_ 483 EPS_4_LatDrvgAvlForLvl 0;
BA_ "GenSigSendType" SG_ 483 EPS_4_Message_Counter 0;
BA_ "GenSigSendType" SG_ 483 EPS_4_CRC 0;
BA_ "VFrameFormat" BO_ 608 14;
BA_ "GenMsgILSupport" BO_ 608 1;
BA_ "GenMsgSendType" BO_ 608 0;
BA_ "GenMsgCycleTime" BO_ 608 20;
BA_ "GenSigSendType" SG_ 608 IPB_LHFWheelSpeedRaw 0;
BA_ "GenSigSendType" SG_ 608 IPB_LHFWheelDriveDirection 0;
BA_ "GenSigInvalidValue" SG_ 608 IPB_LHFWheelDriveDirection 4;
BA_ "GenSigSendType" SG_ 608 IPB_LHFWheelSpeedRawValidData 0;
BA_ "GenSigStartValue" SG_ 608 IPB_LHFWheelSpeedRawValidData 1;
BA_ "GenSigSendType" SG_ 608 IPB_RHFWheelSpeedRaw 0;
BA_ "GenSigSendType" SG_ 608 IPB_RHFWheelDriveDirection 0;
BA_ "GenSigInvalidValue" SG_ 608 IPB_RHFWheelDriveDirection 4;
BA_ "GenSigSendType" SG_ 608 IPB_RHFWheelSpeedRawValidData 0;
BA_ "GenSigStartValue" SG_ 608 IPB_RHFWheelSpeedRawValidData 1;
BA_ "GenSigSendType" SG_ 608 IPB_QDCACC 0;
BA_ "GenSigSendType" SG_ 608 IPB_VLCFail 0;
BA_ "GenSigStartValue" SG_ 608 IPB_VLCFail 1;
BA_ "GenSigSendType" SG_ 608 IPB_ABSESP_7_MessageCounter 0;
BA_ "GenSigSendType" SG_ 608 IPB_ABSESP_7_Checksum 0;
BA_ "VFrameFormat" BO_ 641 14;
BA_ "GenMsgILSupport" BO_ 641 1;
BA_ "GenMsgSendType" BO_ 641 0;
BA_ "GenMsgCycleTime" BO_ 641 20;
BA_ "GenSigSendType" SG_ 641 IPB_LHRWheelSpeedRaw 0;
BA_ "GenSigSendType" SG_ 641 IPB_LHRWheelDriveDirection 0;
BA_ "GenSigInvalidValue" SG_ 641 IPB_LHRWheelDriveDirection 4;
BA_ "GenSigSendType" SG_ 641 IPB_LHRWheelSpeedRawValidData 0;
BA_ "GenSigStartValue" SG_ 641 IPB_LHRWheelSpeedRawValidData 1;
BA_ "GenSigSendType" SG_ 641 IPB_RHRWheelSpeedRaw 0;
BA_ "GenSigSendType" SG_ 641 IPB_RHRWheelDriveDirection 0;
BA_ "GenSigInvalidValue" SG_ 641 IPB_RHRWheelDriveDirection 4;
BA_ "GenSigSendType" SG_ 641 IPB_RHRWheelSpeedRawValidData 0;
BA_ "GenSigStartValue" SG_ 641 IPB_RHRWheelSpeedRawValidData 1;
BA_ "GenSigSendType" SG_ 641 IPB_ABPActive 0;
BA_ "GenSigSendType" SG_ 641 IPB_ABPAvailable 0;
BA_ "GenSigSendType" SG_ 641 IPB_AEBdecActive 0;
BA_ "GenSigSendType" SG_ 641 IPB_AEBdecAvailable 0;
BA_ "GenSigSendType" SG_ 641 IPB_ABSESP_8_MessageCounter 0;
BA_ "GenSigSendType" SG_ 641 IPB_ABSESP_8_Checksum 0;
BA_ "VFrameFormat" BO_ 666 14;
BA_ "GenMsgILSupport" BO_ 666 1;
BA_ "GenMsgSendType" BO_ 666 0;
BA_ "GenMsgCycleTime" BO_ 666 20;
BA_ "GenSigSendType" SG_ 666 IPB_InputRodStroke 0;
BA_ "GenSigStartValue" SG_ 666 IPB_InputRodStroke 100;
BA_ "GenSigSendType" SG_ 666 IPB_InputRodStrokeStatus 0;
BA_ "GenSigSendType" SG_ 666 IPB_ESP_11_MessageCounter 0;
BA_ "GenSigSendType" SG_ 666 IPB_ESP_11_CRC 0;
BA_ "VFrameFormat" BO_ 745 14;
BA_ "GenMsgILSupport" BO_ 745 1;
BA_ "GenMsgSendType" BO_ 745 0;
BA_ "GenMsgCycleTime" BO_ 745 10;
BA_ "GenSigSendType" SG_ 745 IPB_ABS_ESP_1_EBDFailSts 0;
BA_ "GenSigSendType" SG_ 745 IPB_ABS_ESP_1_ABSFailSts 0;
BA_ "GenSigSendType" SG_ 745 IPB_ABS_ESP_1_ABSActive 0;
BA_ "GenSigSendType" SG_ 745 IPB_ABS_ESP_1_VDCFailSts 0;
BA_ "GenSigSendType" SG_ 745 IPB_ABS_ESP_1_VDCActive 0;
BA_ "GenSigSendType" SG_ 745 IPB_ABS_ESP_1_TCSFailSts 0;
BA_ "GenSigSendType" SG_ 745 IPB_ABS_ESP_1_TCSActive 0;
BA_ "GenSigSendType" SG_ 745 IPB_SimulatorPressure 0;
BA_ "GenSigInvalidValue" SG_ 745 IPB_SimulatorPressure 1023;
BA_ "GenSigSendType" SG_ 745 IPB_SimulatorPressureStatus 0;
BA_ "GenSigStartValue" SG_ 745 IPB_SimulatorPressureStatus 1;
BA_ "GenSigSendType" SG_ 745 IPB_ESP1_VehicleSpeedVSOSigValidData 0;
BA_ "GenSigStartValue" SG_ 745 IPB_ESP1_VehicleSpeedVSOSigValidData 1;
BA_ "GenSigSendType" SG_ 745 IPB_ABS_ESP_1_VehicleSpeedVSOSig 0;
BA_ "GenSigInvalidValue" SG_ 745 IPB_ABS_ESP_1_VehicleSpeedVSOSig 8191;
BA_ "GenSigSendType" SG_ 745 IPB_ABS_ESP_1_Checksum 0;
BA_ "GenSigSendType" SG_ 745 IPB_ABS_ESP_1_HDCCtrlSts 0;
BA_ "GenSigSendType" SG_ 745 IPB_ABS_ESP_1_HDCFailSts 0;
BA_ "GenSigSendType" SG_ 745 IPB_ABS_ESP_1_MessageCounter 0;
BA_ "GenSigSendType" SG_ 745 IPB_ABS_ESP_1_ESPSwitchStatus 0;
BA_ "VFrameFormat" BO_ 787 14;
BA_ "GenMsgILSupport" BO_ 787 1;
BA_ "GenMsgSendType" BO_ 787 0;
BA_ "GenMsgCycleTime" BO_ 787 20;
BA_ "GenSigSendType" SG_ 787 IPB_ESP_VLCEngTorqReq 0;
BA_ "GenSigStartValue" SG_ 787 IPB_ESP_VLCEngTorqReq 2000;
BA_ "GenSigInvalidValue" SG_ 787 IPB_ESP_VLCEngTorqReq 4095;
BA_ "GenSigSendType" SG_ 787 IPB_NoBrakeForce 0;
BA_ "GenSigStartValue" SG_ 787 IPB_NoBrakeForce 1;
BA_ "GenSigSendType" SG_ 787 IPB_ABS_ESP_3_AVHFailSts 0;
BA_ "GenSigSendType" SG_ 787 IPB_ABS_ESP_3_AVHSts 0;
BA_ "GenSigSendType" SG_ 787 IPB_ESP_VLCEngTorqReqValidData 0;
BA_ "GenSigStartValue" SG_ 787 IPB_ESP_VLCEngTorqReqValidData 1;
BA_ "GenSigSendType" SG_ 787 IPB_ABS_ESP_3_MessageCounter 0;
BA_ "GenSigSendType" SG_ 787 IPB_ABS_ESP_3_Checksum 0;
BA_ "VFrameFormat" BO_ 790 14;
BA_ "GenMsgILSupport" BO_ 790 1;
BA_ "GenMsgSendType" BO_ 790 0;
BA_ "GenMsgCycleTime" BO_ 790 20;
BA_ "GenSigSendType" SG_ 790 IPB_VLC_InternalTargetAcceleration 0;
BA_ "GenSigStartValue" SG_ 790 IPB_VLC_InternalTargetAcceleration 140;
BA_ "GenSigSendType" SG_ 790 IPB_VehicleStandstill 0;
BA_ "GenSigInvalidValue" SG_ 790 IPB_VehicleStandstill 2;
BA_ "GenSigSendType" SG_ 790 IPB_AWBactive 0;
BA_ "GenSigSendType" SG_ 790 IPB_AWBavailable 0;
BA_ "GenSigSendType" SG_ 790 IPB_ECDTempOff 0;
BA_ "GenSigSendType" SG_ 790 IPB_DCFail 0;
BA_ "GenSigSendType" SG_ 790 IPB_VLC_Active 0;
BA_ "GenSigSendType" SG_ 790 IPB_VLC_Available 0;
BA_ "GenSigSendType" SG_ 790 IPB_CDDActive 0;
BA_ "GenSigSendType" SG_ 790 IPB_CDDAvailable 0;
BA_ "GenSigSendType" SG_ 790 IPB_ABAactive 0;
BA_ "GenSigSendType" SG_ 790 IPB_ABAavailable 0;
BA_ "GenSigSendType" SG_ 790 IPB_ABS_ESP_4_MessageCounter 0;
BA_ "GenSigSendType" SG_ 790 IPB_ABS_ESP_4_Checksum 0;
BA_ "VFrameFormat" BO_ 793 14;
BA_ "GenMsgILSupport" BO_ 793 1;
BA_ "GenMsgSendType" BO_ 793 0;
BA_ "GenMsgCycleTime" BO_ 793 20;
BA_ "GenSigSendType" SG_ 793 IPB_LHRPulseCounter 0;
BA_ "GenSigSendType" SG_ 793 IPB_LHRPulseCounterFailSts 0;
BA_ "GenSigSendType" SG_ 793 IPB_RHFPulseCounterFailSts 0;
BA_ "GenSigSendType" SG_ 793 IPB_LHFPulseCounterFailSts 0;
BA_ "GenSigSendType" SG_ 793 IPB_RHRPulseCounter 0;
BA_ "GenSigSendType" SG_ 793 IPB_RHRPulseCounterFailSts 0;
BA_ "GenSigSendType" SG_ 793 IPB_RHFPulseCounter 0;
BA_ "GenSigSendType" SG_ 793 IPB_LHFPulseCounter 0;
BA_ "GenSigSendType" SG_ 793 IPB_ABS_ESP_5_Reserved1 0;
BA_ "VFrameFormat" BO_ 1270 14;
BA_ "GenMsgILSupport" BO_ 1270 1;
BA_ "GenMsgSendType" BO_ 1270 0;
BA_ "GenMsgCycleTime" BO_ 1270 100;
BA_ "GenSigSendType" SG_ 1270 IPB_EPBErrorStatus 0;
BA_ "GenSigSendType" SG_ 1270 IPB_EPBStatus 0;
BA_ "GenSigStartValue" SG_ 1270 IPB_EPBStatus 4;
VAL_ 773 FRM_3_DxTarObj 0 "No_Display" 1 "Distance_1" 2 "Distance_2" 3 "Distance_3" 4 "Reserved" 5 "Reserved" 6 "Reserved" 7 "Reserved" ;
VAL_ 773 FRM_3_ObjValid 0 "No_Object" 1 "Target_Object_Detected" ;
VAL_ 773 FRM_3_FrontObject_Type 0 "No_Display" 1 "Car" 2 "Truck" 3 "Motorcycle" 4 "Pedestrian" 5 "Bike" 6 "Others" 7 "Reserved" ;
VAL_ 773 FRM_3_Textinfo 0 "No_Display" 1 "ACC_Is_Cancelled" 2 "ACC_Is_Switched_Off" 3 "ACC_Is_Switched_On" 4 "unable_To_Active_ACC" 5 "ACC_Is_Active" 6 "ACC_Is_In_Error_Mode" 7 "Driver_Take_Over" 8 "AEB_Is_Switched_Off" 9 "AEB_Is_Switched_On" 10 "unable_To_Active_AEB" 11 "AEB_Is_Active" 12 "AEB_Is_In_Error_Mode" 13 "Radar_Is_Covered" 14 "FCW_Is_Switched_Off" 15 "FCW_Is_Switched_On" 16 "unable_To_Active_FCW" 17 "distanceWarning_Is_Active" 18 "FCW_Is_Active" 19 "FCW_Is_In_Error_Mode" 20 "Radar_Is_In_Error_Mode" 21 "ACC_Is_Stand_active" 22 "ACC_Is_Stand_wait" ;
VAL_ 773 FRM_3_TakeOverReq 0 "No_Requst" 1 "Requst" ;
VAL_ 773 FRM_3_TimeGapSet_ICM 0 "TauGap_0" 1 "TauGap_1" 2 "TauGap_2" 3 "No_Display" ;
VAL_ 773 FRM_3_ACCMode 0 "OFF_Mode" 1 "Passive_Mode" 2 "Stand-By_Mode" 3 "Active-Control_Mode" 4 "Brake-Only_Mode" 5 "Stand-active" 6 "Stand-wait" 7 "Override" 8 "reserved" 9 "Failure_Mode" ;
VAL_ 773 FRM_3_FCWMode 0 "OFF_Mode" 1 "OnMode" 2 "Active_Mode" 3 "Failure_Mode" ;
VAL_ 773 FRM_3_AEBMode 0 "OFF_Mode" 1 "OnMode" 2 "Active_Mode" 3 "Failure_Mode" ;
VAL_ 773 FRM_3_DistanceWarning 0 "No_Warning" 1 "Warning" ;
VAL_ 773 FRM_3_FCW_PreWarning 0 "No_Warning" 1 "Warning" ;
VAL_ 773 FRM_3_FCW_ON_OFF_Sts 0 "Off" 1 "On" ;
VAL_ 773 FRM_3_FCW_OPTION_Sts 0 "Reserved" 1 "Midder" 2 "Laster" 3 "Earlier" ;
VAL_ 773 FRM_3_AEB_ON_OFF_Sts 0 "Off" 1 "On" ;
VAL_ 775 FCM_2_HMA_Status 0 "Off" 1 "Standby" 2 "Active" 3 "Fault" 4 "Reserved" 5 "Reserved" 6 "Reserved" 7 "Reserved" ;
VAL_ 775 FCM_2_HMA_HighbeamReq 0 "No_Request" 1 "High_Beam_Request" ;
VAL_ 775 FCM_2_HMAOnOffsts 0 "HMA_Not_Selected" 1 "HMA_Selected" 2 "default" ;
VAL_ 775 FCM_2_LDW_LKA_LeftVisualization 0 "No_Display" 1 "Line_Tracking" 2 "Intervention" 3 "Warning" ;
VAL_ 775 FCM_2_LDW_LKA_RightVisualization 0 "No_Display" 1 "Line_Tracking" 2 "Intervention" 3 "Warning" ;
VAL_ 775 FCM_2_TrailorModeSts 0 "Not Active" 1 "Active" 2 "Reserved" 3 "Reserved" ;
VAL_ 775 FCM_2_LDP_Status 0 "Off" 1 "Passive" 2 "Standby" 3 "Active" 4 "Fault" 5 "Reserved" 6 "Reserved" 7 "Reserved" ;
VAL_ 775 FCM_2_LDWLKA_Sensitivityfeedback 0 "LwSensitivity" 1 "HighSensitivity" 2 "Default" 3 "Reserved" ;
VAL_ 775 FCM_2_SLAState 0 "Off" 1 "Fusion_mode(Standby)" 2 "Vision_mode(Active)" 3 "Navigation_only_mode(Reserved)" 4 "Defect(Failure)" 5 "Reserved" 6 "Reserved" 7 "Reserved" ;
VAL_ 775 FCM_2_SLASpdlimit 0 "No_Display" 1 "SPL_Cancelled" 2 "SPL_5" 3 "SPL10" 4 "SPL_15" 5 "SPL_20" 6 "SPL_25" 7 "SPL_30" 8 "SPL_35" 9 "SPL_40" 10 "SPL_45" 11 "SPL_50" 12 "SPL_55" 13 "SPL_60" 14 "SPL_65" 15 "SPL_70" 16 "SPL_75" 17 "SPL_80" 18 "SPL_85" 19 "SPL_90" 20 "SPL_95" 21 "SPL_100" 22 "SPL_105" 23 "SPL_110" 24 "SPL_115" 25 "SPL_120" 26 "SPL_125" 27 "SPL_130" 28 "Reserved" 29 "Reserved" 30 "Reserved" 31 "Reserved" 32 "Reserved" 33 "Reserved" 34 "Reserved" 35 "Reserved" 36 "Reserved" 37 "Reserved" 38 "Reserved" 39 "Reserved" 40 "Reserved" 41 "Reserved" 42 "Reserved" 43 "Reserved" 44 "Reserved" 45 "Reserved" 46 "Reserved" 47 "Reserved" 48 "Reserved" 49 "Reserved" 50 "Reserved" 51 "Reserved" 52 "Reserved" 53 "Reserved" 54 "Reserved" 55 "Reserved" 56 "Reserved" 57 "Reserved" 58 "Reserved" 59 "Reserved" 60 "Reserved" 61 "Reserved" 62 "Reserved" 63 "Reserved" 64 "Reserved" 65 "Reserved" 66 "Reserved" 67 "Reserved" 68 "Reserved" 69 "Reserved" 70 "Reserved" 71 "Reserved" 72 "Reserved" 73 "Reserved" 74 "Reserved" 75 "Reserved" 76 "Reserved" 77 "Reserved" 78 "Reserved" 79 "Reserved" 80 "Reserved" 81 "Reserved" 82 "Reserved" 83 "Reserved" 84 "Reserved" 85 "Reserved" 86 "Reserved" 87 "Reserved" 88 "Reserved" 89 "Reserved" 90 "Reserved" 91 "Reserved" 92 "Reserved" 93 "Reserved" 94 "Reserved" 95 "Reserved" 96 "Reserved" 97 "Reserved" 98 "Reserved" 99 "Reserved" 100 "Reserved" 101 "Reserved" 102 "Reserved" 103 "Reserved" 104 "Reserved" 105 "Reserved" 106 "Reserved" 107 "Reserved" 108 "Reserved" 109 "Reserved" 110 "Reserved" 111 "Reserved" 112 "Reserved" 113 "Reserved" 114 "Reserved" 115 "Reserved" 116 "Reserved" 117 "Reserved" 118 "Reserved" 119 "Reserved" 120 "Reserved" 121 "Reserved" 122 "Reserved" 123 "Reserved" 124 "Reserved" 125 "Reserved" 126 "Reserved" 127 "Reserved" 128 "Reserved" 129 "Reserved" 130 "Reserved" 131 "Reserved" 132 "Reserved" 133 "Reserved" 134 "Reserved" 135 "Reserved" 136 "Reserved" 137 "Reserved" 138 "Reserved" 139 "Reserved" 140 "Reserved" 141 "Reserved" 142 "Reserved" 143 "Reserved" 144 "Reserved" 145 "Reserved" 146 "Reserved" 147 "Reserved" 148 "Reserved" 149 "Reserved" 150 "Reserved" 151 "Reserved" 152 "Reserved" 153 "Reserved" 154 "Reserved" 155 "Reserved" 156 "Reserved" 157 "Reserved" 158 "Reserved" 159 "Reserved" 160 "Reserved" 161 "Reserved" 162 "Reserved" 163 "Reserved" 164 "Reserved" 165 "Reserved" 166 "Reserved" 167 "Reserved" 168 "Reserved" 169 "Reserved" 170 "Reserved" 171 "Reserved" 172 "Reserved" 173 "Reserved" 174 "Reserved" 175 "Reserved" 176 "Reserved" 177 "Reserved" 178 "Reserved" 179 "Reserved" 180 "Reserved" 181 "Reserved" 182 "Reserved" 183 "Reserved" 184 "Reserved" 185 "Reserved" 186 "Reserved" 187 "Reserved" 188 "Reserved" 189 "Reserved" 190 "Reserved" 191 "Reserved" 192 "Reserved" 193 "Reserved" 194 "Reserved" 195 "Reserved" 196 "Reserved" 197 "Reserved" 198 "Reserved" 199 "Reserved" 200 "Reserved" 201 "Reserved" 202 "Reserved" 203 "Reserved" 204 "Reserved" 205 "Reserved" 206 "Reserved" 207 "Reserved" 208 "Reserved" 209 "Reserved" 210 "Reserved" 211 "Reserved" 212 "Reserved" 213 "Reserved" 214 "Reserved" 215 "Reserved" 216 "Reserved" 217 "Reserved" 218 "Reserved" 219 "Reserved" 220 "Reserved" 221 "Reserved" 222 "Reserved" 223 "Reserved" 224 "Reserved" 225 "Reserved" 226 "Reserved" 227 "Reserved" 228 "Reserved" 229 "Reserved" 230 "Reserved" 231 "Reserved" 232 "Reserved" 233 "Reserved" 234 "Reserved" 235 "Reserved" 236 "Reserved" 237 "Reserved" 238 "Reserved" 239 "Reserved" 240 "Reserved" 241 "Reserved" 242 "Reserved" 243 "Reserved" 244 "Reserved" 245 "Reserved" 246 "Reserved" 247 "Reserved" 248 "Reserved" 249 "Reserved" 250 "Reserved" 251 "Reserved" 252 "Reserved" 253 "Reserved" 254 "Reserved" 255 "Reserved" ;
VAL_ 775 FCM_2_SLAOnOffsts 0 "Off" 1 "On" 2 "Default" ;
VAL_ 775 FCM_2_SLASpdlimitWarning 0 "Not_Active" 1 "Active" ;
VAL_ 775 FCM_2_Camera_Textinfo 0 "Camera_Normal" 1 "Camera_Failure" 2 "Camera_Blocked" 3 "Reserved" ;
VAL_ 775 FCM_2_ADAS_TakeoverReq 0 "No_request" 1 "First_level" 2 "Second_level" 3 "Quit" ;
VAL_ 775 FCM_2_TJA_ICA_Textinfo 0 "TJA_ICA_Is_Switched_Off" 1 "TJA_ICA_Is_Switched_On" 2 "Unable_To_Active_TJA_ICA" 3 "TJA_ICA_Is_Active" 4 "TJA_ICA_Is_In_Error_Mode" 5 "TJA_ICA_Is_Exit_reminder" 6 "TJA_ICA_Is_In_ACC_Mode" 7 "No_Display" ;
VAL_ 775 FCM_2_TJA_ICA_Mode 0 "OFF_Mode" 1 "OnMode" 2 "Active_Mode" 3 "Failure_Mode" 4 "Reserved" 5 "Reserved" 6 "Reserved" 7 "Reserved" ;
VAL_ 775 FCM_2_LDWOnOffSts 0 "Off" 1 "On" 2 "Default" 3 "Reserved" ;
VAL_ 775 FCM_2_MessageCounter 15 "Range_High" 0 "Range_Low" ;
VAL_ 775 FCM_2_weather_signal 0 "normal" 1 "Snow" 2 "Rain" 3 "Reserved" ;
VAL_ 809 LDW_Status 0 "Off" 1 "passive" 2 "Standby" 3 "Active" 4 "Fault" 5 "Reserved" 6 "Reserved" 7 "Reserved" ;
VAL_ 809 LDPSwitchFeedback 0 "OFF" 1 "ON" ;
VAL_ 809 IESSwtSetFeedback 0 "OFF" 1 "ON" ;
VAL_ 809 TJA_ICA_WarmingSwitchFeedback 0 "OFF" 1 "ON" ;
VAL_ 837 FCM_3_HptcVibReq 0 "not_request" 1 "request" ;
VAL_ 837 FCM_3_StrngWhlAgReqActive 0 "steering_Wheel_Angle_request_is_not_active" 1 "steering_Wheel_Angle_request_is_active" ;
VAL_ 837 Read2go_Active 0 "Not_Active" 1 "Active" ;
VAL_ 837 Read2go_On_Off_FEEDBACK 0 "OFF" 1 "ON" 2 "Invalid" 3 "Reserved" ;
VAL_ 930 FRM_VLCShutdownMode 0 "Soft_Off" 1 "Fast_Off" 2 "Immediate_Off" 3 "Initial" ;
VAL_ 930 FRM_ACCMode_ESP 0 "OFF_Mode" 1 "Passive_Mode" 2 "Standby_Mode" 3 "Active_Control_Mode" 4 "Brake_Only_Mode" 5 "Override" 6 "Standstill" 7 "Failure_Mode" ;
VAL_ 930 FRM_BrakePreferred 0 "No_Demand" 1 "Demand" ;
VAL_ 930 FRM_DriveOff 0 "No_Demand" 1 "Demand" ;
VAL_ 930 FRM_DecToStop 0 "No_Demand" 1 "Demand" ;
VAL_ 930 FRM_ACC_AccECGPOvrd 0 "No_Demand" 1 "Demand" ;
VAL_ 930 FRM_HBALevel 0 "Level0" 1 "Level1" 2 "Level2" 3 "Level3" ;
VAL_ 930 FRM_HBARequest 0 "No_Demand" 1 "Demand" ;
VAL_ 930 FRM_PrefillRequest 0 "No_Demand" 1 "Demand" ;
VAL_ 933 FRM_AEBDecCtrlRequest 0 "No_Demand" 1 "Demand" ;
VAL_ 933 FRM_ACCMinimumBraking 0 "No_Demand" 1 "Demand" ;
VAL_ 933 FRM_2_ACCStartStopInfo 0 "ACC_StopAllowed" 1 "ACC_StopForbidden" 2 "ACC_StartRequest" 3 "ACC_SystemFailure" ;
VAL_ 933 FRM_AWBRequest 0 "No_Demand" 1 "Demand" ;
VAL_ 933 FRM_AWBLevel 0 "No_Level" 1 "Level1" 2 "Level2" 3 "Level3" 4 "Level4" 5 "Reserved" 6 "Reserved" 7 "Reserved" 8 "Reserved" 9 "Reserved" 10 "Reserved" 11 "Reserved" 12 "Reserved" 13 "Reserved" 14 "Reserved" 15 "Reserved" ;
VAL_ 1020 FCM_10_LDPTJAELKTakeoverReq 0 "Not_Active" 1 "Take_Over_Warning" 2 "Take_Over_Safty" 3 "Suppressed" ;
VAL_ 777 FCM_3_ACCLeftObjectDetected 0 "No_display" 1 "Detected" 2 "Cutin" 3 "Reserved" ;
VAL_ 777 FCM_3_ACCRightObjectDetected 0 "No_display" 1 "Detected" 2 "Cutin" 3 "Reserved" ;
VAL_ 777 FCM_3_FrontObject_IndicatorRight 0 "Off" 1 "On" ;
VAL_ 777 FCM_3_FrontObject_IndicatorLeft 0 "Off" 1 "On" ;
VAL_ 777 FCM_3_FrontObject_BrakeLamp 0 "Off" 1 "On" ;
VAL_ 777 FCM_3_NoLeftTurn_sign 0 "Off" 1 "On" ;
VAL_ 777 FCM_3_NoRightTurn_sign 0 "Off" 1 "On" ;
VAL_ 777 FCM_3_StopSign 0 "Off" 1 "On" ;
VAL_ 777 FCM_3_NOU_turnsign 0 "Off" 1 "On" ;
VAL_ 777 FCM_3_Noentrysign 0 "Off" 1 "On" ;
VAL_ 777 FCM_3_Constructionareasign 0 "Off" 1 "On" ;
VAL_ 777 FCM_3_Crossingsign 0 "Off" 1 "On" ;
VAL_ 777 FCM_3_YieldSIgn 0 "Off" 1 "On" ;
VAL_ 777 FCM_3_NextLeftLane_Mark 0 "No_display" 1 "Solid" 2 "Dashed" 3 "DLM" 4 "Botts" 5 "Deceleration" 6 "HOV_lane" 7 "Reserved" ;
VAL_ 777 FCM_3_NextRightLane_Mark 0 "No_display" 1 "Solid" 2 "Dashed" 3 "DLM" 4 "Botts" 5 "Deceleration" 6 "HOV_lane" 7 "Reserved" ;
VAL_ 785 FCM_4_LeftLane_Mark 0 "No_display" 1 "Solid" 2 "Dashed" 3 "DLM" 4 "Botts" 5 "Deceleration" 6 "HOV_lane" 7 "Reserved" ;
VAL_ 785 FCM_4_RightLane_Mark 0 "No_display" 1 "Solid" 2 "Dashed" 3 "DLM" 4 "Botts" 5 "Deceleration" 6 "HOV_lane" 7 "Reserved" ;
VAL_ 785 FCM_4_ACCLeftObject_Type 0 "No_display" 1 "Car" 2 "Truck" 3 "Motorcycle" 4 "Pedestrian" 5 "Bike" 6 "Others" 7 "Reserved" ;
VAL_ 785 FCM_4_ACCRightObject_Type 0 "No_display" 1 "Car" 2 "Truck" 3 "Motorcycle" 4 "Pedestrian" 5 "Bike" 6 "Others" 7 "Reserved" ;
VAL_ 785 FCM_4__LatFeature_LeftVisualization 0 "No_display" 1 "Line_tracking" 2 "Intervention" 3 "Warning" 4 "LDP_Intervention" 5 "Reserved" 6 "Reserved" 7 "Reserved" ;
VAL_ 785 FCM_4__LatFeature_RightVisualization 0 "No_display" 1 "Line_tracking" 2 "Intervention" 3 "Warning" 4 "LDP_Intervention" 5 "Reserved" 6 "Reserved" 7 "Reserved" ;
VAL_ 196 SAS_1_AngleFailure 0 "No_Failure" 1 "failure" ;
VAL_ 196 SAS_1_SASCalibrated 0 "Not_Calibrated" 1 "Calibrated" ;
VAL_ 196 SAS_1_SteeringAngleValidData 0 "Valid" 1 "NotValid" ;
VAL_ 196 SAS_1_SteeringAngleSpeedValidData 0 "Valid" 1 "NotValid" ;
VAL_ 250 EMS_1_GasPedalPositionInvalidData 0 "Valid" 1 "Not_Valid" ;
VAL_ 250 EMS_1_ECFail 0 "No_Failure" 1 "Failure" ;
VAL_ 250 EMS_1_ECGPOvrd 0 "No_Override" 1 "Driver_Override" ;
VAL_ 250 EMS_1_MessageCounter 15 "Range_High" 0 "Range_Low" ;
VAL_ 257 EMS_2_BrakePedalStsValidDataForTCU 1 "Not_Valid" 0 "Valid" ;
VAL_ 257 EMS_2_BrakePedalStsForTCU 1 "applied" 0 "Not_Applied" ;
VAL_ 257 EMS_2_EngineStsForDCT 0 "Init" 1 "Stop" 2 "ActivatiOnOf_Starter_Powerstage" 3 "Engine_Running" 4 "Engine_Running_In_Limp_Home_Mode" 5 "Reserved" 6 "Reserved" 7 "Invalid" ;
VAL_ 269 PRNDGearAct 0 "Init" 1 "P" 2 "R" 3 "N" 4 "D" 5 "Reserved" 6 "Reserved" 7 "Reserved" ;
VAL_ 269 PRNDGearTarget 0 "Init" 1 "P" 2 "R" 3 "N" 4 "D" 5 "Reserved" 6 "Reserved" 7 "Reserved" ;
VAL_ 269 PRNDGearActValidData 0 "Not_Valid" 1 "Valid" ;
VAL_ 295 CGW_YawrateSigValidData 0 "Valid" 1 "Reserved" 2 "Invalid" 3 "Initialize" ;
VAL_ 295 CGW_LateralAccelerationSigValidData 0 "Valid" 1 "Reserved" 2 "Invalid" 3 "Initialize" ;
VAL_ 296 CGW_LongitudinalAccelerationSigValid 0 "Valid" 1 "Reserved" 2 "Invalid" 3 "Initialize" ;
VAL_ 647 ICM_5_DriverSeatBeltSwitch 0 "Fasten" 1 "Unfasten" ;
VAL_ 647 ICM_5_DriverSeatBeltSwitchQbit 0 "valid" 1 "Invalid" ;
VAL_ 647 ICM_5_ACC_Kilometre_Mile 0 "kilometer" 1 "mile" ;
VAL_ 647 ICM_5_MessageCounter 15 "Range_High" 0 "Range_Low" ;
VAL_ 768 GBPositoionDisplayForPEPS 0 "Reserved" 1 "M1st_Gear_Manual" 2 "M2nd_Gear" 3 "M3rd_Gear" 4 "M4th_Gear" 5 "M5th_Gear" 6 "M6th_Gear" 7 "M7th_Gear" 8 "M8th_Gear" 9 "M9th_Gear" 10 "Low" 11 "Drive" 12 "Neutral" 13 "Reverse" 14 "Park" 15 "Invalid_Limp_Home" ;
VAL_ 768 ActualGear 0 "Reserved" 1 "1st_Gear" 2 "2nd_Gear" 3 "3rd_Gear" 4 "4th_Gear" 5 "5th_Gear" 6 "6th_Gear" 7 "7th_Gear" 8 "8th_Gear" 9 "Reverse" 10 "Neutral" 11 "Park" 12 "9th_Gear" 15 "Invalid_Limp_Home" ;
VAL_ 768 DriverMode 0 "Normal_Mode" 1 "Sport_Mode" 2 "Econ_Mode" 3 "Winter_Mode" ;
VAL_ 768 TargetGearValidData 0 "Not_Valid" 1 "valid" ;
VAL_ 768 ActualGearValidData 0 "Not_Valid" 1 "Valid" ;
VAL_ 768 ShiftInProgress 0 "Not_In_Progress" 1 "In_Progress" ;
VAL_ 768 ShiftInProgressValidData 0 "Valid" 1 "Not_Valid" ;
VAL_ 768 TargetGear 0 "Reserved" 1 "1st_Gear" 2 "2nd_Gear" 3 "3rd_Gear" 4 "4th_Gear" 5 "5th_Gear" 6 "6th_Gear" 7 "7thgear" 8 "8th_Gear" 9 "Reverse" 10 "Neutral" 11 "Park" 12 "9th_Gear" 14 "Reserved" 13 "Reserved" 15 "Invalid_Limp_Home" ;
VAL_ 864 MFS_Cruise_Control 0 "Notaction" 1 "Pressed" 2 "Stuck" 3 "invalid" ;
VAL_ 864 MFS_Seepd_Limit 0 "Notaction" 1 "Pressed" 2 "Stuck" 3 "invalid" ;
VAL_ 864 MFS_Cancel 0 "Notaction" 1 "Pressed" 2 "Stuck" 3 "invalid" ;
VAL_ 864 MFS_RESPlus 0 "Notaction" 1 "Pressed" 2 "Stuck" 3 "invalid" ;
VAL_ 864 MFS_SETMinus 0 "Notaction" 1 "Pressed" 2 "Stuck" 3 "invalid" ;
VAL_ 864 MFS_Time_Gap 0 "Notaction" 1 "Pressed" 2 "Stuck" 3 "invalid" ;
VAL_ 864 MFS_Time_Gap_Add 0 "Notaction" 1 "Pressed" 2 "Stuck" 3 "invalid" ;
VAL_ 864 MFS_Time_Gap_Reduce 0 "Notaction" 1 "Pressed" 2 "Stuck" 3 "invalid" ;
VAL_ 913 BCM_1_HighBeamSts 1 "Active" 0 "Off" ;
VAL_ 913 BCM_1_LowBeamSts 1 "Active" 0 "Off" ;
VAL_ 913 BCM_1_KeySts 0 "OFF" 1 "ACC" 2 "ON" 3 "CRANK_+_ON" ;
VAL_ 913 BCM_1_DirectionIndRight 1 "Active" 0 "Not_Active" ;
VAL_ 913 BCM_1_DirectionIndLeft 1 "Active" 0 "Off" ;
VAL_ 913 BCM_1_HazardLightSW 0 "Not_Active" 1 "Active" ;
VAL_ 913 BCM_1_AutoLightSW 0 "Not_Active" 1 "Active" ;
VAL_ 913 BCM_1_DriverDoorSts 1 "Open" 0 "Close" ;
VAL_ 913 BCM_1_PsngrDoorSts 1 "Open" 0 "Close" ;
VAL_ 913 BCM_1_HoodSts 1 "Open" 0 "Close" ;
VAL_ 913 BCM_1_RHRDoorSts 1 "Open" 0 "Close" ;
VAL_ 913 BCM_1_LHRdoorSts 1 "Open" 0 "Close" ;
VAL_ 913 BCM_1_TrunkSts 1 "Open" 0 "Close" ;
VAL_ 913 BCM_1_DriverDoorStsQbit 0 "valid" 1 "invalid" ;
VAL_ 913 BCM_1_HMASW 0 "Off" 1 "Active" ;
VAL_ 913 BCM_1_FrontFogLightSts 1 "Active" 0 "Off" ;
VAL_ 913 BCM_1_HighBeamSWSts 0 "Off" 1 "Active" ;
VAL_ 913 BCM_1_FlashSWSts 0 "Off" 1 "Active" ;
VAL_ 913 BCM_1_WiperSts 0 "OFF" 1 "Auto_Or_Intermittent" 2 "ContinuousSlow" 3 "ContinuousFast" ;
VAL_ 913 BCM_1_AutoHighSpeedRequest 0 "False" 1 "True" ;
VAL_ 913 BCM_1_RainDetected 0 "False" 1 "True" ;
VAL_ 913 BCM_1_MessageCounter 15 "Range_High" 0 "Range_Low" ;
VAL_ 1034 HCU_PTReady 0 "LmpOFF" 1 "LmpON" ;
VAL_ 1072 ICM_1_MessageCounter 15 "Range_High" 0 "Range_Low" ;
VAL_ 1282 CDPActive 1 "Active" 0 "Not_Active" ;
VAL_ 1282 CDPFailSts 1 "Fail_Present_Lamp_On" 0 "Fail_Not_Present" ;
VAL_ 1333 CLM_2_MessageCounter 15 "Range_High" 0 "Range_Low" ;
VAL_ 1333 CLM_2_ExternalTemperatureFailSts_GS 0 "Fail_Not_Present" 1 "Short_Ground" 2 "Short_Power_Open_Circuit" 3 "Reserved" ;
VAL_ 1335 IHU_9_NavSpeedLimitStatus 0 "SL_UNKNOWN" 1 "SL_EXISTS" 2 "SL_NOLIMIT" 3 "SL_PLURAL" ;
VAL_ 1335 IHU_9_NavSpeedLimit 0 "No_Display" 1 "SPL_5" 2 "SPL_10" 3 "SPL_15" 4 "SPL_20" 5 "SPL_25" 6 "SPL_30" 7 "SPL_35" 8 "SPL_40" 9 "SPL_45" 10 "SPL_50" 11 "SPL_55" 12 "SPL_60" 13 "SPL_65" 14 "SPL_70" 15 "SPL_75" 16 "SPL_80" 17 "SPL_85" 18 "SPL_90" 19 "SPL_95" 20 "SPL_100" 21 "SPL_105" 22 "SPL_110" 23 "SPL_115" 24 "SPL_120" 25 "SPL_125" 26 "SPL_130" 27 "Reserved" 28 "Reserved" 29 "Reserved" 30 "Reserved" 31 "Reserved" 32 "Reserved" 33 "Reserved" 34 "Reserved" 35 "Reserved" 36 "Reserved" 37 "Reserved" 38 "Reserved" 39 "Reserved" 40 "Reserved" 41 "Reserved" 42 "Reserved" 43 "Reserved" 44 "Reserved" 45 "Reserved" 46 "Reserved" 47 "Reserved" 48 "Reserved" 49 "Reserved" 50 "Reserved" 51 "Reserved" 52 "Reserved" 53 "Reserved" 54 "Reserved" 55 "Reserved" 56 "Reserved" 57 "Reserved" 58 "Reserved" 59 "Reserved" 60 "Reserved" 61 "Reserved" 62 "Reserved" 63 "Reserved" ;
VAL_ 1335 IHU_9_NavSpeedLimitUnits 0 "Unknown" 1 "MPH" 2 "KMH" 3 "Reserved" ;
VAL_ 1335 IHU_DriveMode 0 "ECO" 1 "NORMAL" 2 "SPORT" 3 "SNOW" 4 "MUD" 5 "ROCK" 6 "Reserved" 7 "SAND" ;
VAL_ 1335 IHU_9_NavCurrRoadType 0 "Highway" 1 "Nationalway" 2 "Provincialway" 3 "Countylway" 4 "Townway" 5 "CountyandTownlway" 6 "Expressway" 7 "Mainway" 8 "Minorway" 9 "Commonway" 10 "Nonaviway" ;
VAL_ 1276 IHU_11_AEBSwtSet 0 "Not_Active" 1 "ON" 2 "OFF" 3 "Not_Used" ;
VAL_ 1276 IHU_11_FCWSnvtySet 0 "Not_Active" 1 "standard" 2 "near" 3 "far" ;
VAL_ 1276 IHU_11_FCWSwtSet 0 "Not_Active" 1 "ON" 2 "OFF" 3 "Not_Used" ;
VAL_ 1276 IHU_11_TJAICAExitTextInfoSwtSet 0 "Not_Active" 1 "ON" 2 "OFF" 3 "Not_Used" ;
VAL_ 1276 IHU_11_SLASwtSet 0 "Not_Active" 1 "ON" 2 "OFF" 3 "Not_Used" ;
VAL_ 1276 IHU_11_SCFSwtSet 0 "Not_Active" 1 "ON" 2 "OFF" 3 "Not_Used" ;
VAL_ 1276 IHU_11_DAISwtSet 0 "Not_Active" 1 "ON" 2 "OFF" 3 "Not_Used" ;
VAL_ 1276 IHU_11_IESSwtSet 0 "Not_Active" 1 "ON" 2 "OFF" 3 "Not_Used" ;
VAL_ 1276 IHU_11_HMASwtSet 0 "Not_Active" 1 "ON" 2 "OFF" 3 "Not_Used" ;
VAL_ 1276 IHU_11_LDWSwtSet 0 "Not_Active" 1 "ON" 2 "OFF" 3 "Not_Used" ;
VAL_ 1276 IHU_11_LDPSwtSet 0 "Not_Active" 1 "ON" 2 "OFF" 3 "Not_Used" ;
VAL_ 1276 IHU_11_LDWLDPSnvtySet 0 "Not_Active" 1 "LOW" 2 "HIGH" 3 "Not_Used" ;
VAL_ 932 ESP_18_CCO_Active 0 "Not_Active" 1 "Active" 2 "Stand_by" 3 "Failed" ;
VAL_ 1487 TRM_1_MotorHomeConnectSts 0 "Not_active" 1 "Active" ;
VAL_ 916 EPS_TorsionBarTorqueDir 0 "Postive_(CCW)" 1 "Negative_(CW)" ;
VAL_ 916 EPS_TosionBarTorqueValid 0 "Invalid" 1 "Valid" ;
VAL_ 916 EPS_EpsControlStatus 0 "No_Request" 1 "Request_Honored" 2 "Control_Request_Not_Allowed_Temporarily_" 3 "Control_Request_Not_Allowed_Permanent" ;
VAL_ 1285 EPS_1_EPS_AssistanceStyleSts 0 "Heavy" 1 "Light" 2 "Normal" 3 "Not_used" ;
VAL_ 467 EPS_3_StrngWhlAgValid 0 "Valid" 1 "Invalid" ;
VAL_ 467 EPS_3_AgFailr 0 "No_Failure" 1 "Failure" ;
VAL_ 483 EPS_4_LatDrvgAvlForLvl 0 "NotAvailable" 1 "FailureDetected" 2 "Available" 3 "Reserved" ;
VAL_ 608 IPB_LHFWheelDriveDirection 0 "Init" 1 "Forward" 2 "Backward" 3 "Stop" 4 "Invalid" 5 "Reserved" 6 "Reserved" 7 "Reserved" ;
VAL_ 608 IPB_LHFWheelSpeedRawValidData 0 "Valid" 1 "Not_Valid" ;
VAL_ 608 IPB_RHFWheelDriveDirection 0 "Init" 1 "Forward" 2 "Backward" 3 "Stop" 4 "Invalid" 5 "Reserved" 6 "Reserved" 7 "Reserved" ;
VAL_ 608 IPB_RHFWheelSpeedRawValidData 0 "Valid" 1 "Not_Valid" ;
VAL_ 608 IPB_QDCACC 0 "No_Error" 1 "Reversible_Error" 2 "Irreversible_Error" 3 "Not_Defined" ;
VAL_ 608 IPB_VLCFail 0 "No_Error" 1 "Error" ;
VAL_ 641 IPB_LHRWheelDriveDirection 0 "Init" 1 "Forward" 2 "Backward" 3 "Stop" 4 "Invalid" 5 "Reserved" 6 "Reserved" 7 "Reserved" ;
VAL_ 641 IPB_LHRWheelSpeedRawValidData 0 "Valid" 1 "Not_Valid" ;
VAL_ 641 IPB_RHRWheelDriveDirection 0 "Init" 1 "Forward" 2 "Backward" 3 "Stop" 4 "Invalid" 5 "Reserved" 6 "Reserved" 7 "Reserved" ;
VAL_ 641 IPB_RHRWheelSpeedRawValidData 0 "Valid" 1 "Not_Valid" ;
VAL_ 641 IPB_ABPActive 0 "Not_Active" 1 "Active" ;
VAL_ 641 IPB_ABPAvailable 0 "Not_Available" 1 "Available" ;
VAL_ 641 IPB_AEBdecActive 0 "Not_Active" 1 "Active" ;
VAL_ 641 IPB_AEBdecAvailable 0 "Not_Available" 1 "Available" ;
VAL_ 666 IPB_InputRodStrokeStatus 0 "Valid" 1 "Invalid" ;
VAL_ 745 IPB_ABS_ESP_1_EBDFailSts 0 "Not_Present" 1 "Fail_Present_Lamp_On" ;
VAL_ 745 IPB_ABS_ESP_1_ABSFailSts 0 "Not_Present" 1 "Fail_Present_Lamp_On" ;
VAL_ 745 IPB_ABS_ESP_1_ABSActive 0 "Not_Active" 1 "Active" ;
VAL_ 745 IPB_ABS_ESP_1_VDCFailSts 0 "Not_Present" 1 "Fail_Present_Lamp_On" ;
VAL_ 745 IPB_ABS_ESP_1_VDCActive 0 "Not_Active" 1 "Active" ;
VAL_ 745 IPB_ABS_ESP_1_TCSFailSts 0 "Not_Present" 1 "Fail_Present_Lamp_On" ;
VAL_ 745 IPB_ABS_ESP_1_TCSActive 0 "Not_Active" 1 "Active" ;
VAL_ 745 IPB_SimulatorPressureStatus 0 "Valid" 1 "Not_Valid" ;
VAL_ 745 IPB_ESP1_VehicleSpeedVSOSigValidData 0 "Valid" 1 "Not_Valid" ;
VAL_ 745 IPB_ABS_ESP_1_HDCCtrlSts 0 "OFF" 1 "Not_Active_Braking_Lamp_On" 2 "Active_Braking_Lamp_Flash" 3 "Not_Used" ;
VAL_ 745 IPB_ABS_ESP_1_HDCFailSts 0 "Not_Present" 1 "Fail_Present_Lamp_On" ;
VAL_ 745 IPB_ABS_ESP_1_ESPSwitchStatus 0 "On" 1 "Disable" ;
VAL_ 787 IPB_NoBrakeForce 0 "Exist_Brake_Force" 1 "No_Brake_Force" ;
VAL_ 787 IPB_ABS_ESP_3_AVHFailSts 0 "Not_Present" 1 "Fail_Present_Lamp_On" ;
VAL_ 787 IPB_ABS_ESP_3_AVHSts 0 "Off" 1 "Standby" 2 "Active" 3 "Not_Used" ;
VAL_ 787 IPB_ESP_VLCEngTorqReqValidData 0 "Not_Present" 1 "Fail_Present_Lamp_On" ;
VAL_ 790 IPB_VehicleStandstill 0 "Not_Standstill" 1 "Standstill" 2 "Invalid" 3 "Reserved" ;
VAL_ 790 IPB_AWBactive 0 "Not_Active" 1 "Active" ;
VAL_ 790 IPB_AWBavailable 0 "Not_Available" 1 "Available" ;
VAL_ 790 IPB_ECDTempOff 1 "Temp_Too_High" 0 "Not_High" ;
VAL_ 790 IPB_DCFail 0 "No_Error" 1 "Error" ;
VAL_ 790 IPB_VLC_Active 0 "Not_Active" 1 "Active" ;
VAL_ 790 IPB_VLC_Available 0 "Not_Available" 1 "Available" ;
VAL_ 790 IPB_CDDActive 0 "Not_Active" 1 "Active" ;
VAL_ 790 IPB_CDDAvailable 0 "Not_Available" 1 "Available" ;
VAL_ 790 IPB_ABAactive 0 "Not_Active" 1 "Active" ;
VAL_ 790 IPB_ABAavailable 0 "Not_Available" 1 "Available" ;
VAL_ 793 IPB_LHRPulseCounterFailSts 0 "Fail_Not_Present" 1 "Fail_Present" ;
VAL_ 793 IPB_RHFPulseCounterFailSts 0 "Fail_Not_Present" 1 "Fail_Present" ;
VAL_ 793 IPB_LHFPulseCounterFailSts 0 "Fail_Not_Present" 1 "Fail_Present" ;
VAL_ 793 IPB_RHRPulseCounterFailSts 0 "Fail_Not_Present" 1 "Fail_Present" ;
VAL_ 1270 IPB_EPBErrorStatus 0 "No_Error" 1 "Error" ;
VAL_ 1270 IPB_EPBStatus 0 "Released" 1 "Applied" 2 "Releasing" 3 "Applying" 4 "Unknown" 5 "ErrorApplied" 6 "Not_Used" 7 "Not_Used" ;
